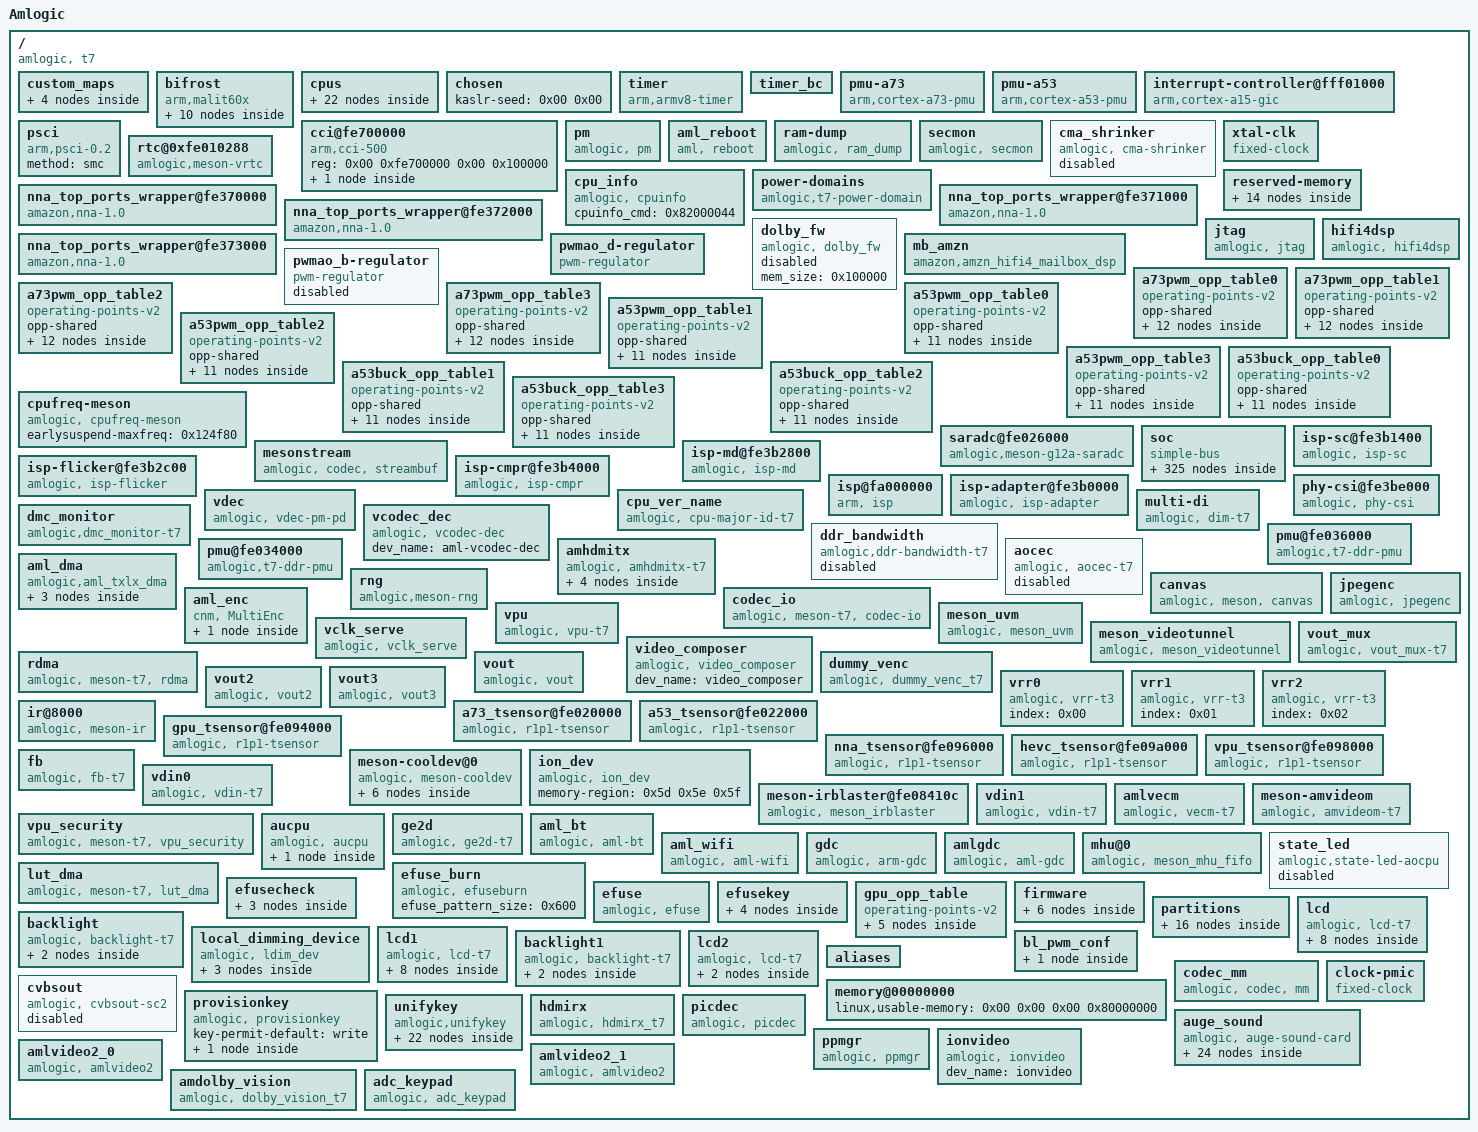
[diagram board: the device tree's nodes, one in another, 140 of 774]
/dts-v1/;

/ {
	model = "Amlogic";
	amlogic-dt-id = "t7_carmel_rev01";
	compatible = "amlogic, t7";
	interrupt-parent = <0x01>;
	#address-cells = <0x02>;
	#size-cells = <0x02>;

	custom_maps {
		mapnum = <0x04>;
		map0 = <0x02>;
		map1 = <0x03>;
		map2 = <0x04>;
		map3 = <0x05>;
		phandle = <0x5c>;

		map_0 {
			mapname = "amlogic-remote-1";
			customcode = <0xfb04>;
			release_delay = <0x50>;
			size = <0x33>;
			keymap = <0x47000b 0x130002 0x100003 0x110004 0xf0005 0xc0006 0xd0007 0xb0008 0x80009 0x9000a 0x5c0061 0x51003d 0x50003e 0x40003f 0x4d0040 0x430041 0x170042 0x43 0x10044 0x160057 0x49000e 0x60082 0x140083 0x440067 0x1d006c 0x1c0069 0x48006a 0x53007d 0x450068 0x19006d 0x520077 0x5007a 0x59007b 0x1b0078 0x40079 0x1a0074 0xa000f 0xe0071 0x1f0066 0x1e0084 0x70085 0x120086 0x540087 0x20088 0x4f001e 0x420030 0x5d002e 0x4c0020 0x580089 0x1500d9 0x55008c>;
			phandle = <0x02>;
		};

		map_1 {
			mapname = "amlogic-remote-2";
			customcode = <0xfe01>;
			release_delay = <0x50>;
			size = <0x35>;
			keymap = <0x10002 0x20003 0x30004 0x40005 0x50006 0x60007 0x70008 0x80009 0x9000a 0xa000b 0x1f01d2 0x15008b 0x16000f 0xc0192 0xd0193 0xe0073 0xf0072 0x110066 0x1c006a 0x1b0069 0x190067 0x1a006c 0x1d001c 0x170071 0x4900db 0x43009e 0x1201d5 0x1401d6 0x1801d7 0x590166 0x5a00a6 0x100074 0x4200a5 0x4400a3 0x1e00a8 0x4b00d0 0x5800a4 0x460082 0x400083 0x380046 0x5701d0 0x5b01d1 0x54018e 0x4c018f 0x4e0190 0x550191 0x5300ed 0x5200ee 0x3900d4 0x4100d5 0xb00d6 0xd8 0x1300d9>;
			phandle = <0x03>;
		};

		map_2 {
			mapname = "amlogic-remote-3";
			customcode = <0xbd02>;
			release_delay = <0x50>;
			size = <0x11>;
			keymap = <0xca0067 0xd2006c 0x990069 0xc1006a 0xce0061 0x450074 0xc50085 0x800071 0xd0000f 0xd6007d 0x950066 0xdd0068 0x8c006d 0x890083 0x9c0082 0x9a0078 0xcd0079>;
			phandle = <0x04>;
		};

		map_3 {
			mapname = "amlogic-remote-4";
			customcode = <0x7788>;
			release_delay = <0x50>;
			vendor = <0x02>;
			product = <0x02>;
			version = <0x200>;
			size = <0x26>;
			keymap = <0x10002 0x20003 0x30004 0x40005 0x50006 0x60007 0x70008 0x80009 0x9000a 0xa000b 0x5801d7 0x290166 0x74009c 0x4600d9 0xf008d 0x150067 0x16006c 0x170069 0x18006a 0x19001c 0x470066 0x48009e 0x32008a 0x210074 0x6001d2 0x250071 0x230073 0x240072 0x6300bb 0x6400bc 0x6700bd 0x6800be 0x330192 0x340193 0x4b018e 0x4a018f 0x490190 0x4c0191>;
			phandle = <0x05>;
		};
	};

	bifrost {
		compatible = "arm,malit60x\0arm,malit6xx\0arm,mali-midgard";
		#cooling-cells = <0x02>;
		reg = <0x00 0xfe400000 0x00 0x4000 0x00 0xfe002000 0x00 0x1000 0x00 0xff800000 0x00 0x1000 0x00 0xfe000000 0x00 0x1000 0x00 0xfe002000 0x00 0x1000>;
		interrupt-parent = <0x01>;
		interrupts = <0x00 0x90 0x04 0x00 0x91 0x04 0x00 0x92 0x04>;
		interrupt-names = "GPU\0MMU\0JOB";
		num_of_pp = <0x04>;
		sc_mpp = <0x01>;
		tbl = <0x06 0x07 0x08 0x09 0x0a 0x0a>;
		operating-points-v2 = <0x0b>;
		power-domains = <0x0c 0x1b>;
		system-coherency = <0x00>;
		clocks = <0x0d 0x8b>;
		clock-names = "gpu_mux";
		assigned-clocks = <0x0d 0x85 0x0d 0x87 0x0d 0x8b>;
		assigned-clock-parents = <0x0d 0x0f 0x00 0x0d 0x87>;
		assigned-clock-rates = <0x00 0x2faf0800 0x00>;

		clk125_cfg {
			clk_freq = <0x7735940>;
			clk_parent = "fclk_div4";
			clkp_freq = <0x1dcd6500>;
			clk_reg = <0xa03>;
			voltage = <0x47e>;
			keep_count = <0x05>;
			threshold = <0x1e 0x78>;
		};

		dvfs250_cfg {
			clk_freq = <0xee6b280>;
			clk_parent = "fclk_div4";
			clkp_freq = <0x1dcd6500>;
			clk_reg = <0xa01>;
			voltage = <0x47e>;
			keep_count = <0x05>;
			threshold = <0x00 0x4c>;
			phandle = <0x06>;
		};

		dvfs285_cfg {
			clk_freq = <0x1107a76d>;
			clk_parent = "fclk_div7";
			clkp_freq = <0x1107a76d>;
			clk_reg = <0xe00>;
			voltage = <0x47e>;
			keep_count = <0x05>;
			threshold = <0x00 0x4c>;
		};

		dvfs400_cfg {
			clk_freq = <0x17d78400>;
			clk_parent = "fclk_div5";
			clkp_freq = <0x17d78400>;
			clk_reg = <0xc00>;
			voltage = <0x47e>;
			keep_count = <0x05>;
			threshold = <0x50 0x78>;
			phandle = <0x07>;
		};

		dvfs500_cfg {
			clk_freq = <0x1dcd6500>;
			clk_parent = "fclk_div4";
			clkp_freq = <0x1dcd6500>;
			clk_reg = <0xa00>;
			voltage = <0x47e>;
			keep_count = <0x05>;
			threshold = <0x50 0x78>;
			phandle = <0x08>;
		};

		dvfs666_cfg {
			clk_freq = <0x27bc86aa>;
			clk_parent = "fclk_div3";
			clkp_freq = <0x27bc86aa>;
			clk_reg = <0x800>;
			voltage = <0x47e>;
			keep_count = <0x05>;
			threshold = <0x50 0x78>;
			phandle = <0x09>;
		};

		dvfs800_cfg {
			clk_freq = <0x2faf0800>;
			clk_parent = "fclk_div2p5";
			clkp_freq = <0x2faf0800>;
			clk_reg = <0x600>;
			voltage = <0x47e>;
			keep_count = <0x05>;
			threshold = <0x50 0xff>;
			phandle = <0x0a>;
		};

		dvfs850_cfg {
			clk_freq = <0x326cef80>;
			clk_parent = "gp0_pll";
			clkp_freq = <0x326cef80>;
			clk_reg = <0x200>;
			voltage = <0x47e>;
			keep_count = <0x05>;
			threshold = <0x50 0xff>;
		};

		reset_cfg {
			reg_level = <0x11>;
			reg_mask = <0x21>;
			reg_bit = <0x02>;
		};

		capb_reset {
			reg_level = <0x11>;
			reg_mask = <0x21>;
			reg_bit = <0x01>;
		};
	};

	cpus {
		#address-cells = <0x02>;
		#size-cells = <0x00>;

		cpu-map {

			cluster0 {

				core0 {
					cpu = <0x0e>;
				};

				core1 {
					cpu = <0x0f>;
				};

				core2 {
					cpu = <0x10>;
				};

				core3 {
					cpu = <0x11>;
				};
			};

			cluster1 {

				core0 {
					cpu = <0x12>;
				};

				core1 {
					cpu = <0x13>;
				};

				core2 {
					cpu = <0x14>;
				};

				core3 {
					cpu = <0x15>;
				};
			};
		};

		cpu@0 {
			device_type = "cpu";
			compatible = "arm,cortex-a73\0arm,armv8";
			reg = <0x00 0x00>;
			enable-method = "psci";
			cpu-idle-states = <0x16 0x17>;
			clocks = <0x0d 0x19 0x0d 0x18 0x0d 0x03>;
			clock-names = "core_clk\0low_freq_clk_parent\0high_freq_clk_parent";
			voltage-tolerance = <0x00>;
			clock-latency = <0xc350>;
			capacity-dmips-mhz = <0x400>;
			dynamic-power-coefficient = <0x226>;
			#cooling-cells = <0x02>;
			cpu-supply = <0x18>;
			multi_tables_available;
			operating-points-v2 = <0x19 0x1a 0x1b 0x1c>;
			phandle = <0x0e>;
		};

		cpu@1 {
			device_type = "cpu";
			compatible = "arm,cortex-a73\0arm,armv8";
			reg = <0x00 0x01>;
			enable-method = "psci";
			cpu-idle-states = <0x16 0x17>;
			clocks = <0x0d 0x19 0x0d 0x18 0x0d 0x03>;
			clock-names = "core_clk\0low_freq_clk_parent\0high_freq_clk_parent";
			voltage-tolerance = <0x00>;
			clock-latency = <0xc350>;
			capacity-dmips-mhz = <0x400>;
			dynamic-power-coefficient = <0x226>;
			#cooling-cells = <0x02>;
			cpu-supply = <0x18>;
			multi_tables_available;
			operating-points-v2 = <0x19 0x1a 0x1b 0x1c>;
			phandle = <0x0f>;
		};

		cpu@2 {
			device_type = "cpu";
			compatible = "arm,cortex-a73\0arm,armv8";
			reg = <0x00 0x02>;
			enable-method = "psci";
			cpu-idle-states = <0x16 0x17>;
			clocks = <0x0d 0x19 0x0d 0x18 0x0d 0x03>;
			clock-names = "core_clk\0low_freq_clk_parent\0high_freq_clk_parent";
			voltage-tolerance = <0x00>;
			clock-latency = <0xc350>;
			capacity-dmips-mhz = <0x400>;
			dynamic-power-coefficient = <0x226>;
			#cooling-cells = <0x02>;
			cpu-supply = <0x18>;
			multi_tables_available;
			operating-points-v2 = <0x19 0x1a 0x1b 0x1c>;
			phandle = <0x10>;
		};

		cpu@3 {
			device_type = "cpu";
			compatible = "arm,cortex-a73\0arm,armv8";
			reg = <0x00 0x03>;
			enable-method = "psci";
			cpu-idle-states = <0x16 0x17>;
			clocks = <0x0d 0x19 0x0d 0x18 0x0d 0x03>;
			clock-names = "core_clk\0low_freq_clk_parent\0high_freq_clk_parent";
			voltage-tolerance = <0x00>;
			clock-latency = <0xc350>;
			capacity-dmips-mhz = <0x400>;
			dynamic-power-coefficient = <0x226>;
			#cooling-cells = <0x02>;
			cpu-supply = <0x18>;
			multi_tables_available;
			operating-points-v2 = <0x19 0x1a 0x1b 0x1c>;
			phandle = <0x11>;
		};

		cpu@100 {
			device_type = "cpu";
			compatible = "arm,cortex-a53\0arm,armv8";
			reg = <0x00 0x100>;
			enable-method = "psci";
			cpu-idle-states = <0x16 0x17>;
			clocks = <0x0d 0x17 0x0d 0x16 0x0d 0x15>;
			clock-names = "core_clk\0low_freq_clk_parent\0high_freq_clk_parent";
			voltage-tolerance = <0x00>;
			clock-latency = <0xc350>;
			capacity-dmips-mhz = <0x278>;
			dynamic-power-coefficient = <0x6e>;
			#cooling-cells = <0x02>;
			cpu-supply = <0x1d>;
			cpu_reg_use_buck;
			multi_tables_available;
			operating-points-v2 = <0x1e 0x1f 0x20 0x21>;
			phandle = <0x12>;
		};

		cpu@101 {
			device_type = "cpu";
			compatible = "arm,cortex-a53\0arm,armv8";
			reg = <0x00 0x101>;
			enable-method = "psci";
			cpu-idle-states = <0x16 0x17>;
			clocks = <0x0d 0x17 0x0d 0x16 0x0d 0x15>;
			clock-names = "core_clk\0low_freq_clk_parent\0high_freq_clk_parent";
			voltage-tolerance = <0x00>;
			clock-latency = <0xc350>;
			capacity-dmips-mhz = <0x278>;
			dynamic-power-coefficient = <0x6e>;
			#cooling-cells = <0x02>;
			cpu-supply = <0x1d>;
			cpu_reg_use_buck;
			multi_tables_available;
			operating-points-v2 = <0x1e 0x1f 0x20 0x21>;
			phandle = <0x13>;
		};

		cpu@102 {
			device_type = "cpu";
			compatible = "arm,cortex-a53\0arm,armv8";
			reg = <0x00 0x102>;
			enable-method = "psci";
			cpu-idle-states = <0x16 0x17>;
			clocks = <0x0d 0x17 0x0d 0x16 0x0d 0x15>;
			clock-names = "core_clk\0low_freq_clk_parent\0high_freq_clk_parent";
			voltage-tolerance = <0x00>;
			clock-latency = <0xc350>;
			capacity-dmips-mhz = <0x278>;
			dynamic-power-coefficient = <0x6e>;
			#cooling-cells = <0x02>;
			cpu-supply = <0x1d>;
			cpu_reg_use_buck;
			multi_tables_available;
			operating-points-v2 = <0x1e 0x1f 0x20 0x21>;
			phandle = <0x14>;
		};

		cpu@103 {
			device_type = "cpu";
			compatible = "arm,cortex-a53\0arm,armv8";
			reg = <0x00 0x103>;
			enable-method = "psci";
			cpu-idle-states = <0x16 0x17>;
			clocks = <0x0d 0x17 0x0d 0x16 0x0d 0x15>;
			clock-names = "core_clk\0low_freq_clk_parent\0high_freq_clk_parent";
			voltage-tolerance = <0x00>;
			clock-latency = <0xc350>;
			capacity-dmips-mhz = <0x278>;
			dynamic-power-coefficient = <0x6e>;
			#cooling-cells = <0x02>;
			cpu-supply = <0x1d>;
			cpu_reg_use_buck;
			multi_tables_available;
			operating-points-v2 = <0x1e 0x1f 0x20 0x21>;
			phandle = <0x15>;
		};

		idle-states {
			entry-method = "arm,psci-0.2";

			cpu-sleep-0 {
				compatible = "arm,idle-state";
				arm,psci-suspend-param = <0x10000>;
				local-timer-stop;
				entry-latency-us = <0x1f4>;
				exit-latency-us = <0x3e8>;
				min-residency-us = <0x7d0>;
				phandle = <0x16>;
			};

			system-sleep-0 {
				compatible = "arm,idle-state";
				arm,psci-suspend-param = <0x00>;
				entry-latency-us = <0x3fffffff>;
				exit-latency-us = <0x40000000>;
				min-residency-us = <0xffffffff>;
				phandle = <0x17>;
			};
		};
	};

	chosen {
		kaslr-seed = <0x00 0x00>;
	};

	timer {
		compatible = "arm,armv8-timer";
		interrupts = <0x01 0x0d 0xff08 0x01 0x0e 0xff08 0x01 0x0b 0xff08 0x01 0x0a 0xff08>;
	};

	timer_bc {
		reg = <0x00 0xfe0100d8 0x00 0x04 0x00 0xfe0100dc 0x00 0x04>;
		timer_name = "Meson TimerD";
		clockevent-rating = <0x12c>;
		clockevent-shift = <0x14>;
		clockevent-features = <0x23>;
		interrupts = <0x00 0x03 0x01>;
		bit_enable = <0x07>;
		bit_mode = <0x06>;
		bit_resolution = <0x00>;
		resolution_1us = <0x01>;
		min_delta_ns = <0x0a>;
	};

	pmu-a73 {
		compatible = "arm,cortex-a73-pmu";
		private-interrupts;
		interrupts = <0x00 0x109 0x04 0x00 0x10a 0x04 0x00 0x10b 0x04 0x00 0x10c 0x04>;
		interrupt-affinity = <0x0e 0x0f 0x10 0x11>;
	};

	pmu-a53 {
		compatible = "arm,cortex-a53-pmu";
		private-interrupts;
		interrupts = <0x00 0xe9 0x04 0x00 0xea 0x04 0x00 0xeb 0x04 0x00 0xec 0x04>;
		interrupt-affinity = <0x12 0x13 0x14 0x15>;
	};

	interrupt-controller@fff01000 {
		compatible = "arm,cortex-a15-gic\0arm,cortex-a9-gic";
		#interrupt-cells = <0x03>;
		#address-cells = <0x00>;
		interrupt-controller;
		reg = <0x00 0xfff01000 0x00 0x1000 0x00 0xfff02000 0x00 0x100>;
		interrupts = <0x01 0x09 0xf04>;
		phandle = <0x01>;
	};

	cci@fe700000 {
		compatible = "arm,cci-500";
		#address-cells = <0x01>;
		#size-cells = <0x01>;
		reg = <0x00 0xfe700000 0x00 0x100000>;
		ranges = <0x00 0x00 0xfe700000 0x100000>;

		pmu@10000 {
			compatible = "arm,cci-500-pmu,r0";
			reg = <0x10000 0x80000>;
			interrupts = <0x00 0x4f 0x04 0x00 0x4f 0x04 0x00 0x4f 0x04 0x00 0x4f 0x04 0x00 0x4f 0x04 0x00 0x4f 0x04 0x00 0x4f 0x04 0x00 0x4f 0x04>;
		};
	};

	psci {
		compatible = "arm,psci-0.2";
		method = "smc";
	};

	pm {
		compatible = "amlogic, pm";
		status = "okay";
		device_name = "aml_pm";
		reg = <0x00 0xfe010288 0x00 0x04 0x00 0xfe0102dc 0x00 0x04>;
	};

	aml_reboot {
		compatible = "aml, reboot";
		sys_reset = <0x84000009>;
		sys_poweroff = <0x84000008>;
		dis_nb_cpus_in_shutdown;
	};

	ram-dump {
		compatible = "amlogic, ram_dump";
		status = "okay";
		reg = <0x00 0xfe0102d8 0x00 0x04>;
		reg-names = "SYSCTRL_STICKY_REG6";
		store_device = "data";
	};

	secmon {
		compatible = "amlogic, secmon";
		memory-region = <0x22>;
		in_base_func = <0x82000020>;
		out_base_func = <0x82000021>;
		inout_size_func = <0x8200002a>;
		reserve_mem_size = <0x3300000>;
		clear_range = <0x5100000 0x2a00000>;
	};

	cma_shrinker {
		compatible = "amlogic, cma-shrinker";
		status = "disabled";
		adj = <0x00 0x64 0xc8 0xfa 0x384 0x3b6>;
		free = <0x2000 0x3000 0x4000 0x6000 0x7000 0x8000>;
	};

	xtal-clk {
		compatible = "fixed-clock";
		clock-frequency = <0x16e3600>;
		clock-output-names = "xtal";
		#clock-cells = <0x00>;
		phandle = <0x2a>;
	};

	cpu_info {
		compatible = "amlogic, cpuinfo";
		status = "okay";
		cpuinfo_cmd = <0x82000044>;
	};

	rtc@0xfe010288 {
		compatible = "amlogic,meson-vrtc";
		reg = <0x00 0xfe010288 0x00 0x04>;
		status = "okay";
		mboxes = <0x23 0x05>;
	};

	power-domains {
		compatible = "amlogic,t7-power-domain";
		#power-domain-cells = <0x01>;
		status = "okay";
		phandle = <0x0c>;
	};

	reserved-memory {
		#address-cells = <0x02>;
		#size-cells = <0x02>;
		ranges;

		acenna_reserved {
			compatible = "shared-dma-pool";
			size = <0x00 0xb000000>;
			alloc-ranges = <0x00 0x00 0x00 0x80000000>;
			reusable;
			phandle = <0x24>;
		};

		ramoops@0x07400000 {
			compatible = "ramoops";
			reg = <0x00 0x7400000 0x00 0x100000>;
			record-size = <0x20000>;
			console-size = <0x40000>;
			ftrace-size = <0x80000>;
			pmsg-size = <0x20000>;
		};

		linux,secmon {
			compatible = "shared-dma-pool";
			reusable;
			size = <0x00 0x3400000>;
			alignment = <0x00 0x400000>;
			alloc-ranges = <0x00 0x5000000 0x00 0x3400000>;
			clear-map;
			phandle = <0x22>;
		};

		linux,dsp_fw {
			compatible = "shared-dma-pool";
			reusable;
			size = <0x00 0x1000000>;
			alignment = <0x00 0x400000>;
			alloc-ranges = <0x00 0x40000000 0x00 0x1000000>;
			phandle = <0x27>;
		};

		linux,meson-fb {
			compatible = "shared-dma-pool";
			reusable;
			size = <0x00 0x800000>;
			alignment = <0x00 0x400000>;
			alloc-ranges = <0x00 0x3f800000 0x00 0x800000>;
			phandle = <0x60>;
		};

		linux,codec_mm_cma {
			compatible = "shared-dma-pool";
			reusable;
			size = <0x00 0x1b000000>;
			alignment = <0x00 0x400000>;
			linux,contiguous-region;
			clear-map;
			phandle = <0x8c>;
		};

		linux,di_cma {
			compatible = "shared-dma-pool";
			reusable;
			size = <0x00 0xb000000>;
			alignment = <0x00 0x400000>;
		};

		linux,ppmgr {
			compatible = "shared-dma-pool";
			size = <0x00 0x00>;
			phandle = <0xb3>;
		};

		linux,ion-dev {
			compatible = "shared-dma-pool";
			reusable;
			size = <0x00 0xa000000>;
			alignment = <0x00 0x400000>;
			alloc-ranges = <0x00 0x00 0x40000000 0x40000000>;
			phandle = <0x5d>;
		};

		linux,ion-camera {
			compatible = "shared-dma-pool";
			reusable;
			size = <0x00 0x4000000>;
			alignment = <0x00 0x400000>;
			alloc-ranges = <0x00 0x00 0x40000000 0x40000000>;
			phandle = <0x5f>;
		};

		linux,ion-secure {
			compatible = "amlogic, ion-secure-mem";
			no-map;
			size = <0x00 0x00>;
			alignment = <0x00 0x400000>;
			phandle = <0x5e>;
		};

		linux,ion-fb {
			compatible = "shared-dma-pool";
			reusable;
			size = <0x00 0x1c00000>;
			alignment = <0x00 0x400000>;
		};

		linux,codec_mm_reserved {
			compatible = "amlogic, codec-mm-reserved";
			size = <0x00 0x00>;
			alignment = <0x00 0x100000>;
			phandle = <0x8d>;
		};

		linux,vdin1_cma {
			compatible = "shared-dma-pool";
			reusable;
			size = <0x00 0x1400000>;
			alignment = <0x00 0x400000>;
			phandle = <0x62>;
		};
	};

	nna_top_ports_wrapper@fe370000 {
		compatible = "amazon,nna-1.0";
		device-name = "acenna0";
		status = "okay";
		clocks = <0x0d 0x155>;
		clock-names = "nna_clk_gate";
		assigned-clocks = <0x0d 0x14e 0x0d 0x154 0x0d 0x155>;
		assigned-clock-parents = <0x0d 0x0f 0x0d 0x150 0x00>;
		assigned-clock-rates = <0x00 0x00 0x2faf0800>;
		interrupt-names = "nna_interrupt";
		interrupts = <0x00 0xb9 0x01>;
		memory-region = <0x24>;
		minor-number = <0x00>;
		power-domains = <0x0c 0x1e 0x0c 0x20>;
		power-domain-names = "pwrc-core\0pwrc-top";
		reg = <0x00 0xfe370000 0x00 0x1000>;
		reg-names = "nna_irq_wrapper";
	};

	nna_top_ports_wrapper@fe371000 {
		compatible = "amazon,nna-1.0";
		device-name = "acenna1";
		status = "okay";
		clocks = <0x0d 0x155>;
		clock-names = "nna_clk_gate";
		assigned-clocks = <0x0d 0x14e 0x0d 0x154 0x0d 0x155>;
		assigned-clock-parents = <0x0d 0x0f 0x0d 0x150 0x00>;
		assigned-clock-rates = <0x00 0x00 0x2faf0800>;
		interrupt-names = "nna_interrupt";
		interrupts = <0x00 0xba 0x01>;
		minor-number = <0x01>;
		power-domains = <0x0c 0x1f 0x0c 0x20>;
		power-domain-names = "pwrc-core\0pwrc-top";
		reg = <0x00 0xfe371000 0x00 0x1000>;
		reg-names = "nna_irq_wrapper";
	};

	nna_top_ports_wrapper@fe372000 {
		compatible = "amazon,nna-1.0";
		device-name = "acenna2";
		status = "okay";
		clocks = <0x0d 0x155>;
		clock-names = "nna_clk_gate";
		assigned-clocks = <0x0d 0x14e 0x0d 0x154 0x0d 0x155>;
		assigned-clock-parents = <0x0d 0x0f 0x0d 0x150 0x00>;
		assigned-clock-rates = <0x00 0x00 0x2faf0800>;
		interrupt-names = "nna_interrupt";
		interrupts = <0x00 0xbb 0x01>;
		minor-number = <0x02>;
		power-domains = <0x0c 0x1c 0x0c 0x20>;
		power-domain-names = "pwrc-core\0pwrc-top";
		reg = <0x00 0xfe372000 0x00 0x1000>;
		reg-names = "nna_irq_wrapper";
	};

	nna_top_ports_wrapper@fe373000 {
		compatible = "amazon,nna-1.0";
		device-name = "acenna3";
		status = "okay";
		clocks = <0x0d 0x155>;
		clock-names = "nna_clk_gate";
		assigned-clocks = <0x0d 0x14e 0x0d 0x154 0x0d 0x155>;
		assigned-clock-parents = <0x0d 0x0f 0x0d 0x150 0x00>;
		assigned-clock-rates = <0x00 0x00 0x2faf0800>;
		interrupt-names = "nna_interrupt";
		interrupts = <0x00 0xbc 0x01>;
		minor-number = <0x03>;
		power-domains = <0x0c 0x1d 0x0c 0x20>;
		power-domain-names = "pwrc-core\0pwrc-top";
		reg = <0x00 0xfe373000 0x00 0x1000>;
		reg-names = "nna_irq_wrapper";
	};

	dolby_fw {
		compatible = "amlogic, dolby_fw";
		mem_size = <0x100000>;
		status = "disabled";
	};

	jtag {
		compatible = "amlogic, jtag";
		status = "okay";
		select = "disable";
		pinctrl-names = "jtag_a_pins\0jtag_b_pins";
		pinctrl-0 = <0x25>;
		pinctrl-1 = <0x26>;
	};

	hifi4dsp {
		compatible = "amlogic, hifi4dsp";
		memory-region = <0x27>;
		reg = <0x00 0xfe340018 0x00 0x114 0x00 0xfe350018 0x00 0x114 0x00 0xfe010258 0x00 0x04 0x00 0xfe01025c 0x00 0x04 0x00 0x40b80000 0x00 0x80000>;
		dsp-monitor-period-ms = <0x3e8>;
		reg-names = "dspa_top_reg\0dspb_top_reg";
		clocks = <0x0d 0x55 0x0d 0x133>;
		clock-names = "dspa_clk\0dspb_clk";
		dsp-start-mode = <0x01>;
		dsp-cnt = <0x02>;
		dspaoffset = <0x00>;
		dspboffset = <0xc00000>;
		bootlocation = <0x01>;
		optimize_longcall = <0x01 0x01>;
		sram_remap_addr = <0x42000000 0xf7000000 0x42100000 0xf7100000>;
		boot_sram_addr = <0xfff00000>;
		boot_sram_size = <0x80000>;
		power-domains = <0x0c 0x00 0x0c 0x01>;
		power-domain-names = "dspa\0dspb";
		status = "okay";
	};

	mb_amzn {
		status = "okay";
		compatible = "amazon,amzn_hifi4_mailbox_dsp";
	};

	pwmao_d-regulator {
		compatible = "pwm-regulator";
		pwms = <0x28 0x01 0x5dc 0x00>;
		regulator-name = "vddcpua";
		regulator-min-microvolt = <0xa8368>;
		regulator-max-microvolt = <0x1001a8>;
		regulator-always-on;
		max-duty-cycle = <0x5dc>;
		voltage-table = <0x1001a8 0x00 0xfda98 0x03 0xfb388 0x06 0xf8c78 0x09 0xf6568 0x0c 0xf3e58 0x0e 0xf1748 0x11 0xef038 0x14 0xec928 0x17 0xea218 0x1a 0xe7b08 0x1d 0xe53f8 0x1f 0xe2ce8 0x22 0xe05d8 0x25 0xddec8 0x28 0xdb7b8 0x2b 0xd90a8 0x2d 0xd6998 0x30 0xd4288 0x33 0xd1b78 0x36 0xcf468 0x38 0xccd58 0x3b 0xca648 0x3e 0xc7f38 0x41 0xc5828 0x44 0xc3118 0x46 0xc0a08 0x49 0xbe2f8 0x4c 0xbbbe8 0x4f 0xb94d8 0x51 0xb6dc8 0x54 0xb46b8 0x57 0xb1fa8 0x59 0xaf898 0x5c 0xad188 0x5f 0xaaa78 0x62 0xa8368 0x64>;
		status = "okay";
		phandle = <0x18>;
	};

	pwmao_b-regulator {
		compatible = "pwm-regulator";
		pwms = <0x29 0x01 0x5dc 0x00>;
		regulator-name = "vddcpub";
		regulator-min-microvolt = <0xa8368>;
		regulator-max-microvolt = <0x1001a8>;
		regulator-always-on;
		max-duty-cycle = <0x5dc>;
		voltage-table = <0x1001a8 0x00 0xfda98 0x03 0xfb388 0x06 0xf8c78 0x09 0xf6568 0x0c 0xf3e58 0x0e 0xf1748 0x11 0xef038 0x14 0xec928 0x17 0xea218 0x1a 0xe7b08 0x1d 0xe53f8 0x1f 0xe2ce8 0x22 0xe05d8 0x25 0xddec8 0x28 0xdb7b8 0x2b 0xd90a8 0x2d 0xd6998 0x30 0xd4288 0x33 0xd1b78 0x36 0xcf468 0x38 0xccd58 0x3b 0xca648 0x3e 0xc7f38 0x41 0xc5828 0x44 0xc3118 0x46 0xc0a08 0x49 0xbe2f8 0x4c 0xbbbe8 0x4f 0xb94d8 0x51 0xb6dc8 0x54 0xb46b8 0x57 0xb1fa8 0x59 0xaf898 0x5c 0xad188 0x5f 0xaaa78 0x62 0xa8368 0x64>;
		status = "disabled";
	};

	a73pwm_opp_table0 {
		compatible = "operating-points-v2";
		opp-shared;
		phandle = <0x19>;

		opp00 {
			opp-hz = <0x00 0x1dcd6500>;
			opp-microvolt = <0xc7f38>;
		};

		opp01 {
			opp-hz = <0x00 0x27b25a80>;
			opp-microvolt = <0xc7f38>;
		};

		opp02 {
			opp-hz = <0x00 0x3b9aca00>;
			opp-microvolt = <0xc7f38>;
		};

		opp03 {
			opp-hz = <0x00 0x47868c00>;
			opp-microvolt = <0xc7f38>;
		};

		opp04 {
			opp-hz = <0x00 0x52f83c00>;
			opp-microvolt = <0xc7f38>;
		};

		opp05 {
			opp-hz = <0x00 0x5a1f4a00>;
			opp-microvolt = <0xca648>;
		};

		opp06 {
			opp-hz = <0x00 0x5fd82200>;
			opp-microvolt = <0xcf468>;
		};

		opp07 {
			opp-hz = <0x00 0x6590fa00>;
			opp-microvolt = <0xd4288>;
		};

		opp08 {
			opp-hz = <0x00 0x6b49d200>;
			opp-microvolt = <0xddec8>;
		};

		opp09 {
			opp-hz = <0x00 0x7102aa00>;
			opp-microvolt = <0xe53f8>;
		};

		opp10 {
			opp-hz = <0x00 0x7829b800>;
			opp-microvolt = <0xea218>;
		};

		opp11 {
			opp-hz = <0x00 0x839b6800>;
			opp-microvolt = <0xf6568>;
		};
	};

	a73pwm_opp_table1 {
		compatible = "operating-points-v2";
		opp-shared;
		phandle = <0x1a>;

		opp00 {
			opp-hz = <0x00 0x1dcd6500>;
			opp-microvolt = <0xc7f38>;
		};

		opp01 {
			opp-hz = <0x00 0x27b25a80>;
			opp-microvolt = <0xc7f38>;
		};

		opp02 {
			opp-hz = <0x00 0x3b9aca00>;
			opp-microvolt = <0xc7f38>;
		};

		opp03 {
			opp-hz = <0x00 0x47868c00>;
			opp-microvolt = <0xc7f38>;
		};

		opp04 {
			opp-hz = <0x00 0x52f83c00>;
			opp-microvolt = <0xc7f38>;
		};

		opp05 {
			opp-hz = <0x00 0x5a1f4a00>;
			opp-microvolt = <0xca648>;
		};

		opp06 {
			opp-hz = <0x00 0x5fd82200>;
			opp-microvolt = <0xcf468>;
		};

		opp07 {
			opp-hz = <0x00 0x6590fa00>;
			opp-microvolt = <0xd4288>;
		};

		opp08 {
			opp-hz = <0x00 0x6b49d200>;
			opp-microvolt = <0xddec8>;
		};

		opp09 {
			opp-hz = <0x00 0x7102aa00>;
			opp-microvolt = <0xe53f8>;
		};

		opp10 {
			opp-hz = <0x00 0x7829b800>;
			opp-microvolt = <0xea218>;
		};

		opp11 {
			opp-hz = <0x00 0x839b6800>;
			opp-microvolt = <0xf6568>;
		};
	};

	a73pwm_opp_table2 {
		compatible = "operating-points-v2";
		opp-shared;
		phandle = <0x1b>;

		opp00 {
			opp-hz = <0x00 0x1dcd6500>;
			opp-microvolt = <0xc3118>;
		};

		opp01 {
			opp-hz = <0x00 0x27b25a80>;
			opp-microvolt = <0xc3118>;
		};

		opp02 {
			opp-hz = <0x00 0x3b9aca00>;
			opp-microvolt = <0xc3118>;
		};

		opp03 {
			opp-hz = <0x00 0x47868c00>;
			opp-microvolt = <0xc3118>;
		};

		opp04 {
			opp-hz = <0x00 0x52f83c00>;
			opp-microvolt = <0xc5828>;
		};

		opp05 {
			opp-hz = <0x00 0x5a1f4a00>;
			opp-microvolt = <0xc5828>;
		};

		opp06 {
			opp-hz = <0x00 0x5fd82200>;
			opp-microvolt = <0xca648>;
		};

		opp07 {
			opp-hz = <0x00 0x6590fa00>;
			opp-microvolt = <0xcf468>;
		};

		opp08 {
			opp-hz = <0x00 0x6b49d200>;
			opp-microvolt = <0xd1b78>;
		};

		opp09 {
			opp-hz = <0x00 0x7102aa00>;
			opp-microvolt = <0xd90a8>;
		};

		opp10 {
			opp-hz = <0x00 0x7829b800>;
			opp-microvolt = <0xe05d8>;
		};

		opp11 {
			opp-hz = <0x00 0x839b6800>;
			opp-microvolt = <0xec928>;
		};
	};

	a73pwm_opp_table3 {
		compatible = "operating-points-v2";
		opp-shared;
		phandle = <0x1c>;

		opp00 {
			opp-hz = <0x00 0x1dcd6500>;
			opp-microvolt = <0xc0a08>;
		};

		opp01 {
			opp-hz = <0x00 0x27b25a80>;
			opp-microvolt = <0xc0a08>;
		};

		opp02 {
			opp-hz = <0x00 0x3b9aca00>;
			opp-microvolt = <0xc0a08>;
		};

		opp03 {
			opp-hz = <0x00 0x47868c00>;
			opp-microvolt = <0xc0a08>;
		};

		opp04 {
			opp-hz = <0x00 0x52f83c00>;
			opp-microvolt = <0xc5828>;
		};

		opp05 {
			opp-hz = <0x00 0x5a1f4a00>;
			opp-microvolt = <0xc5828>;
		};

		opp06 {
			opp-hz = <0x00 0x5fd82200>;
			opp-microvolt = <0xc7f38>;
		};

		opp07 {
			opp-hz = <0x00 0x6590fa00>;
			opp-microvolt = <0xca648>;
		};

		opp08 {
			opp-hz = <0x00 0x6b49d200>;
			opp-microvolt = <0xcf468>;
		};

		opp09 {
			opp-hz = <0x00 0x7102aa00>;
			opp-microvolt = <0xd1b78>;
		};

		opp10 {
			opp-hz = <0x00 0x7829b800>;
			opp-microvolt = <0xd6998>;
		};

		opp11 {
			opp-hz = <0x00 0x839b6800>;
			opp-microvolt = <0xe05d8>;
		};
	};

	a53pwm_opp_table0 {
		compatible = "operating-points-v2";
		opp-shared;

		opp00 {
			opp-hz = <0x00 0x1dcd6500>;
			opp-microvolt = <0xbbbe8>;
		};

		opp01 {
			opp-hz = <0x00 0x27b25a80>;
			opp-microvolt = <0xbbbe8>;
		};

		opp02 {
			opp-hz = <0x00 0x3b9aca00>;
			opp-microvolt = <0xbbbe8>;
		};

		opp03 {
			opp-hz = <0x00 0x47868c00>;
			opp-microvolt = <0xbbbe8>;
		};

		opp04 {
			opp-hz = <0x00 0x52f83c00>;
			opp-microvolt = <0xbbbe8>;
		};

		opp05 {
			opp-hz = <0x00 0x5a1f4a00>;
			opp-microvolt = <0xc5828>;
		};

		opp06 {
			opp-hz = <0x00 0x5fd82200>;
			opp-microvolt = <0xccd58>;
		};

		opp07 {
			opp-hz = <0x00 0x6590fa00>;
			opp-microvolt = <0xd4288>;
		};

		opp08 {
			opp-hz = <0x00 0x6b49d200>;
			opp-microvolt = <0xddec8>;
		};

		opp09 {
			opp-hz = <0x00 0x7102aa00>;
			opp-microvolt = <0xe7b08>;
		};

		opp10 {
			opp-hz = <0x00 0x7829b800>;
			opp-microvolt = <0xf6568>;
		};
	};

	a53pwm_opp_table1 {
		compatible = "operating-points-v2";
		opp-shared;

		opp00 {
			opp-hz = <0x00 0x1dcd6500>;
			opp-microvolt = <0xbbbe8>;
		};

		opp01 {
			opp-hz = <0x00 0x27b25a80>;
			opp-microvolt = <0xbbbe8>;
		};

		opp02 {
			opp-hz = <0x00 0x3b9aca00>;
			opp-microvolt = <0xbbbe8>;
		};

		opp03 {
			opp-hz = <0x00 0x47868c00>;
			opp-microvolt = <0xbbbe8>;
		};

		opp04 {
			opp-hz = <0x00 0x52f83c00>;
			opp-microvolt = <0xbbbe8>;
		};

		opp05 {
			opp-hz = <0x00 0x5a1f4a00>;
			opp-microvolt = <0xc5828>;
		};

		opp06 {
			opp-hz = <0x00 0x5fd82200>;
			opp-microvolt = <0xccd58>;
		};

		opp07 {
			opp-hz = <0x00 0x6590fa00>;
			opp-microvolt = <0xd4288>;
		};

		opp08 {
			opp-hz = <0x00 0x6b49d200>;
			opp-microvolt = <0xddec8>;
		};

		opp09 {
			opp-hz = <0x00 0x7102aa00>;
			opp-microvolt = <0xe7b08>;
		};

		opp10 {
			opp-hz = <0x00 0x7829b800>;
			opp-microvolt = <0xf6568>;
		};
	};

	a53pwm_opp_table2 {
		compatible = "operating-points-v2";
		opp-shared;

		opp00 {
			opp-hz = <0x00 0x1dcd6500>;
			opp-microvolt = <0xb94d8>;
		};

		opp01 {
			opp-hz = <0x00 0x27b25a80>;
			opp-microvolt = <0xb94d8>;
		};

		opp02 {
			opp-hz = <0x00 0x3b9aca00>;
			opp-microvolt = <0xb94d8>;
		};

		opp03 {
			opp-hz = <0x00 0x47868c00>;
			opp-microvolt = <0xb94d8>;
		};

		opp04 {
			opp-hz = <0x00 0x52f83c00>;
			opp-microvolt = <0xbbbe8>;
		};

		opp05 {
			opp-hz = <0x00 0x5a1f4a00>;
			opp-microvolt = <0xc0a08>;
		};

		opp06 {
			opp-hz = <0x00 0x5fd82200>;
			opp-microvolt = <0xc3118>;
		};

		opp07 {
			opp-hz = <0x00 0x6590fa00>;
			opp-microvolt = <0xca648>;
		};

		opp08 {
			opp-hz = <0x00 0x6b49d200>;
			opp-microvolt = <0xd1b78>;
		};

		opp09 {
			opp-hz = <0x00 0x7102aa00>;
			opp-microvolt = <0xdb7b8>;
		};

		opp10 {
			opp-hz = <0x00 0x7829b800>;
			opp-microvolt = <0xe7b08>;
		};
	};

	a53pwm_opp_table3 {
		compatible = "operating-points-v2";
		opp-shared;

		opp00 {
			opp-hz = <0x00 0x1dcd6500>;
			opp-microvolt = <0xb6dc8>;
		};

		opp01 {
			opp-hz = <0x00 0x27b25a80>;
			opp-microvolt = <0xb6dc8>;
		};

		opp02 {
			opp-hz = <0x00 0x3b9aca00>;
			opp-microvolt = <0xb6dc8>;
		};

		opp03 {
			opp-hz = <0x00 0x47868c00>;
			opp-microvolt = <0xb6dc8>;
		};

		opp04 {
			opp-hz = <0x00 0x52f83c00>;
			opp-microvolt = <0xbbbe8>;
		};

		opp05 {
			opp-hz = <0x00 0x5a1f4a00>;
			opp-microvolt = <0xbe2f8>;
		};

		opp06 {
			opp-hz = <0x00 0x5fd82200>;
			opp-microvolt = <0xc0a08>;
		};

		opp07 {
			opp-hz = <0x00 0x6590fa00>;
			opp-microvolt = <0xc5828>;
		};

		opp08 {
			opp-hz = <0x00 0x6b49d200>;
			opp-microvolt = <0xca648>;
		};

		opp09 {
			opp-hz = <0x00 0x7102aa00>;
			opp-microvolt = <0xd1b78>;
		};

		opp10 {
			opp-hz = <0x00 0x7829b800>;
			opp-microvolt = <0xe05d8>;
		};
	};

	a53buck_opp_table0 {
		compatible = "operating-points-v2";
		opp-shared;
		phandle = <0x1e>;

		opp00 {
			opp-hz = <0x00 0x1dcd6500>;
			opp-microvolt = <0xbbfd0>;
		};

		opp01 {
			opp-hz = <0x00 0x27b25a80>;
			opp-microvolt = <0xbbfd0>;
		};

		opp02 {
			opp-hz = <0x00 0x3b9aca00>;
			opp-microvolt = <0xbbfd0>;
		};

		opp03 {
			opp-hz = <0x00 0x47868c00>;
			opp-microvolt = <0xbbfd0>;
		};

		opp04 {
			opp-hz = <0x00 0x52f83c00>;
			opp-microvolt = <0xbbfd0>;
		};

		opp05 {
			opp-hz = <0x00 0x5a1f4a00>;
			opp-microvolt = <0xc5c10>;
		};

		opp06 {
			opp-hz = <0x00 0x5fd82200>;
			opp-microvolt = <0xcd140>;
		};

		opp07 {
			opp-hz = <0x00 0x6590fa00>;
			opp-microvolt = <0xd4670>;
		};

		opp08 {
			opp-hz = <0x00 0x6b49d200>;
			opp-microvolt = <0xde2b0>;
		};

		opp09 {
			opp-hz = <0x00 0x7102aa00>;
			opp-microvolt = <0xe7ef0>;
		};

		opp10 {
			opp-hz = <0x00 0x7829b800>;
			opp-microvolt = <0xf6950>;
		};
	};

	a53buck_opp_table1 {
		compatible = "operating-points-v2";
		opp-shared;
		phandle = <0x1f>;

		opp00 {
			opp-hz = <0x00 0x1dcd6500>;
			opp-microvolt = <0xbbfd0>;
		};

		opp01 {
			opp-hz = <0x00 0x27b25a80>;
			opp-microvolt = <0xbbfd0>;
		};

		opp02 {
			opp-hz = <0x00 0x3b9aca00>;
			opp-microvolt = <0xbbfd0>;
		};

		opp03 {
			opp-hz = <0x00 0x47868c00>;
			opp-microvolt = <0xbbfd0>;
		};

		opp04 {
			opp-hz = <0x00 0x52f83c00>;
			opp-microvolt = <0xbbfd0>;
		};

		opp05 {
			opp-hz = <0x00 0x5a1f4a00>;
			opp-microvolt = <0xc5c10>;
		};

		opp06 {
			opp-hz = <0x00 0x5fd82200>;
			opp-microvolt = <0xcd140>;
		};

		opp07 {
			opp-hz = <0x00 0x6590fa00>;
			opp-microvolt = <0xd4670>;
		};

		opp08 {
			opp-hz = <0x00 0x6b49d200>;
			opp-microvolt = <0xde2b0>;
		};

		opp09 {
			opp-hz = <0x00 0x7102aa00>;
			opp-microvolt = <0xe7ef0>;
		};

		opp10 {
			opp-hz = <0x00 0x7829b800>;
			opp-microvolt = <0xf6950>;
		};
	};

	a53buck_opp_table2 {
		compatible = "operating-points-v2";
		opp-shared;
		phandle = <0x20>;

		opp00 {
			opp-hz = <0x00 0x1dcd6500>;
			opp-microvolt = <0xb98c0>;
		};

		opp01 {
			opp-hz = <0x00 0x27b25a80>;
			opp-microvolt = <0xb98c0>;
		};

		opp02 {
			opp-hz = <0x00 0x3b9aca00>;
			opp-microvolt = <0xb98c0>;
		};

		opp03 {
			opp-hz = <0x00 0x47868c00>;
			opp-microvolt = <0xb98c0>;
		};

		opp04 {
			opp-hz = <0x00 0x52f83c00>;
			opp-microvolt = <0xbbfd0>;
		};

		opp05 {
			opp-hz = <0x00 0x5a1f4a00>;
			opp-microvolt = <0xc0df0>;
		};

		opp06 {
			opp-hz = <0x00 0x5fd82200>;
			opp-microvolt = "\0\f5";
		};

		opp07 {
			opp-hz = <0x00 0x6590fa00>;
			opp-microvolt = <0xcaa30>;
		};

		opp08 {
			opp-hz = <0x00 0x6b49d200>;
			opp-microvolt = <0xd1f60>;
		};

		opp09 {
			opp-hz = <0x00 0x7102aa00>;
			opp-microvolt = <0xdbba0>;
		};

		opp10 {
			opp-hz = <0x00 0x7829b800>;
			opp-microvolt = <0xe7ef0>;
		};
	};

	a53buck_opp_table3 {
		compatible = "operating-points-v2";
		opp-shared;
		phandle = <0x21>;

		opp00 {
			opp-hz = <0x00 0x1dcd6500>;
			opp-microvolt = <0xb71b0>;
		};

		opp01 {
			opp-hz = <0x00 0x27b25a80>;
			opp-microvolt = <0xb71b0>;
		};

		opp02 {
			opp-hz = <0x00 0x3b9aca00>;
			opp-microvolt = <0xb71b0>;
		};

		opp03 {
			opp-hz = <0x00 0x47868c00>;
			opp-microvolt = <0xb71b0>;
		};

		opp04 {
			opp-hz = <0x00 0x52f83c00>;
			opp-microvolt = <0xbbfd0>;
		};

		opp05 {
			opp-hz = <0x00 0x5a1f4a00>;
			opp-microvolt = <0xbe6e0>;
		};

		opp06 {
			opp-hz = <0x00 0x5fd82200>;
			opp-microvolt = <0xc0df0>;
		};

		opp07 {
			opp-hz = <0x00 0x6590fa00>;
			opp-microvolt = <0xc5c10>;
		};

		opp08 {
			opp-hz = <0x00 0x6b49d200>;
			opp-microvolt = <0xcaa30>;
		};

		opp09 {
			opp-hz = <0x00 0x7102aa00>;
			opp-microvolt = <0xd1f60>;
		};

		opp10 {
			opp-hz = <0x00 0x7829b800>;
			opp-microvolt = <0xe09c0>;
		};
	};

	cpufreq-meson {
		compatible = "amlogic, cpufreq-meson";
		earlysuspend-maxfreq = <0x124f80>;
		status = "okay";
	};

	saradc@fe026000 {
		compatible = "amlogic,meson-g12a-saradc\0amlogic,meson-saradc";
		status = "okay";
		#io-channel-cells = <0x01>;
		clocks = <0x2a 0x0d 0x1aa 0x0d 0x129 0x0d 0x127>;
		clock-names = "clkin\0core\0adc_clk\0adc_sel";
		interrupts = <0x00 0xb5 0x01>;
		reg = <0x00 0xfe026000 0x00 0x48>;
		phandle = <0xb4>;
	};

	soc {
		compatible = "simple-bus";
		#address-cells = <0x02>;
		#size-cells = <0x02>;
		ranges;

		apb4@fe000000 {
			compatible = "simple-bus";
			reg = <0x00 0xfe000000 0x00 0x480000>;
			#address-cells = <0x02>;
			#size-cells = <0x02>;
			ranges = <0x00 0x00 0x00 0xfe000000 0x00 0x480000>;

			clock-controller {
				compatible = "amlogic,t7-clkc";
				#clock-cells = <0x01>;
				reg = <0x00 0x00 0x00 0x49c 0x00 0x8000 0x00 0x320 0x00 0xe040 0x00 0xbc>;
				reg-names = "basic\0pll\0cpu_clk";
				clocks = <0x2a>;
				clock-names = "xtal";
				status = "okay";
				phandle = <0x0d>;
			};

			meson_clk_msr@48000 {
				compatible = "amlogic,meson-t7-clk-measure";
				reg = <0x00 0x48000 0x00 0x1c>;
			};

			meson_ring_msr {
				compatible = "amlogic,meson-t7-ring-msr";
				status = "okay";
			};

			watchdog@2100 {
				compatible = "amlogic,meson-sc2-wdt";
				status = "okay";
				amlogic,feed_watchdog_mode = <0x01>;
				reg = <0x00 0x2100 0x00 0x10>;
				clocks = <0x2a>;
			};

			pinctrl@4000 {
				compatible = "amlogic,meson-t7-periphs-pinctrl";
				#address-cells = <0x02>;
				#size-cells = <0x02>;
				ranges;
				phandle = <0x2b>;

				bank@4000 {
					reg = <0x00 0x4000 0x00 0x64 0x00 0x40c0 0x00 0x220>;
					reg-names = "mux\0gpio";
					gpio-controller;
					#gpio-cells = <0x02>;
					gpio-ranges = <0x2b 0x00 0x00 0x9d>;
					phandle = <0x2d>;
				};

				i2c0_pins1 {

					mux {
						groups = "i2c0_sda_t\0i2c0_sck_t";
						function = "i2c0";
						drive-strength-microamp = <0xbb8>;
						bias-disable;
					};
				};

				i2c0_pins2 {

					mux {
						groups = "i2c0_sda_h\0i2c0_sck_h";
						function = "i2c0";
						drive-strength-microamp = <0xbb8>;
						bias-disable;
					};
				};

				i2c1_pins1 {
					phandle = <0x31>;

					mux {
						groups = "i2c1_sda\0i2c1_sck";
						function = "i2c1";
						drive-strength-microamp = <0x1f4>;
						bias-disable;
					};
				};

				i2c2_pins1 {

					mux {
						groups = "i2c2_sda_x\0i2c2_sck_x";
						function = "i2c2";
						drive-strength-microamp = <0xbb8>;
						bias-disable;
					};
				};

				i2c2_pins2 {

					mux {
						groups = "i2c2_sda_t\0i2c2_sck_t";
						function = "i2c2";
						drive-strength-microamp = <0xbb8>;
						bias-disable;
					};
				};

				i2c2_pins3 {

					mux {
						groups = "i2c2_sda_m\0i2c2_sck_m";
						function = "i2c2";
						drive-strength-microamp = <0xbb8>;
						bias-disable;
					};
				};

				i2c3_pins1 {

					mux {
						groups = "i2c3_sda_m\0i2c3_sck_m";
						function = "i2c3";
						drive-strength-microamp = <0xbb8>;
						bias-disable;
					};
				};

				i2c3_pins2 {

					mux {
						groups = "i2c3_sda_h\0i2c3_sck_h";
						function = "i2c3";
						drive-strength-microamp = <0x1f4>;
						bias-disable;
					};
				};

				i2c4_pins1 {

					mux {
						groups = "i2c4_sda_y\0i2c4_sck_y";
						function = "i2c4";
						drive-strength-microamp = <0xbb8>;
						bias-disable;
					};
				};

				i2c4_pins2 {

					mux {
						groups = "i2c4_sda_h\0i2c4_sck_h";
						function = "i2c4";
						drive-strength-microamp = <0xbb8>;
						bias-disable;
					};
				};

				i2c5_pins1 {

					mux {
						groups = "i2c5_sda\0i2c5_sck";
						function = "i2c5";
						drive-strength-microamp = <0xbb8>;
						bias-disable;
					};
				};

				i2c0_ao_pins1 {
					phandle = <0x32>;

					mux {
						groups = "i2c0_ao_sda_d\0i2c0_ao_sck_d";
						function = "i2c0_ao";
						drive-strength-microamp = <0xbb8>;
						bias-disable;
					};
				};

				i2c0_ao_pins2 {

					mux {
						groups = "i2c0_ao_sda_e\0i2c0_ao_sck_e";
						function = "i2c0_ao";
						drive-strength-microamp = <0xbb8>;
						bias-disable;
					};
				};

				i2c1_ao_pins1 {

					mux {
						groups = "i2c1_ao_sda\0i2c1_ao_sck";
						function = "i2c1_ao";
						drive-strength-microamp = <0xbb8>;
						bias-disable;
					};
				};

				a_uart1 {

					mux {
						groups = "uart_a_tx_d2\0uart_a_rx_d3";
						function = "uart_a";
					};
				};

				a_uart2 {

					mux {
						groups = "uart_a_tx_d8\0uart_a_rx_d9";
						function = "uart_a";
					};
				};

				b_uart {
					phandle = <0x35>;

					mux {
						groups = "uart_ao_b_tx\0uart_ao_b_rx";
						function = "uart_ao_b";
					};
				};

				c_uart {
					phandle = <0x4e>;

					mux {
						groups = "uart_c_tx\0uart_c_rx\0uart_c_cts\0uart_c_rts";
						bias-pull-up;
						output-high;
						function = "uart_c";
					};
				};

				d_uart1 {
					phandle = <0x4f>;

					mux {
						groups = "uart_d_tx_m\0uart_d_rx_m";
						function = "uart_d";
					};
				};

				d_uart2 {

					mux {
						groups = "uart_d_tx_y\0uart_d_rx_y";
						function = "uart_d";
					};
				};

				e_uart {
					phandle = <0x50>;

					mux {
						groups = "uart_e_tx\0uart_e_rx\0uart_e_cts\0uart_e_rts";
						bias-pull-up;
						output-high;
						function = "uart_e";
					};
				};

				f_uart {
					phandle = <0x51>;

					mux {
						groups = "uart_f_tx\0uart_f_rx";
						function = "uart_f";
					};
				};

				emmc {
					phandle = <0x45>;

					mux-0 {
						groups = "emmc_nand_d0\0emmc_nand_d1\0emmc_nand_d2\0emmc_nand_d3\0emmc_nand_d4\0emmc_nand_d5\0emmc_nand_d6\0emmc_nand_d7\0emmc_cmd";
						function = "emmc";
						bias-pull-up;
						drive-strength-microamp = <0xfa0>;
					};

					mux-1 {
						groups = "emmc_clk";
						function = "emmc";
						bias-disable;
						drive-strength-microamp = <0xfa0>;
					};
				};

				emmc-ds {
					phandle = <0x46>;

					mux {
						groups = "emmc_nand_ds";
						function = "emmc";
						bias-pull-down;
						drive-strength-microamp = <0xfa0>;
					};
				};

				emmc_clk_gate {
					phandle = <0x47>;

					mux {
						groups = "GPIOB_8";
						function = "gpio_periphs";
						bias-pull-down;
						drive-strength-microamp = <0xfa0>;
					};
				};

				sd_clk_cmd_pins {

					mux {
						groups = "sdcard_cmd";
						function = "sdcard";
						bias-pull-up;
						drive-strength-microamp = <0xfa0>;
					};

					mux1 {
						groups = "sdcard_clk";
						function = "sdcard";
						bias-pull-up;
						drive-strength-microamp = <0xfa0>;
					};
				};

				sd_all_pins {
					phandle = <0x48>;

					mux {
						groups = "sdcard_d0\0sdcard_d1\0sdcard_d2\0sdcard_d3\0sdcard_cmd";
						function = "sdcard";
						bias-pull-up;
						drive-strength-microamp = <0xfa0>;
					};

					mux1 {
						groups = "sdcard_clk";
						function = "sdcard";
						bias-pull-up;
						drive-strength-microamp = <0xfa0>;
					};
				};

				sd_clk_gate {
					phandle = <0x4a>;

					mux {
						groups = "GPIOC_4";
						function = "gpio_periphs";
						bias-pull-down;
						drive-strength-microamp = <0xfa0>;
					};
				};

				sd_all_pd_pins {

					mux {
						groups = "GPIOC_0\0GPIOC_1\0GPIOC_2\0GPIOC_3\0GPIOC_4\0GPIOC_5";
						function = "gpio_periphs";
						bias-pull-down;
						output-low;
					};
				};

				sd_1bit_pins {
					phandle = <0x49>;

					mux {
						groups = "sdcard_d0\0sdcard_cmd";
						function = "sdcard";
						bias-pull-up;
						drive-strength-microamp = <0xfa0>;
					};

					mux1 {
						groups = "sdcard_clk";
						function = "sdcard";
						bias-pull-up;
						drive-strength-microamp = <0xfa0>;
					};
				};

				sd_clr_all_pins {

					mux {
						groups = "GPIOC_0\0GPIOC_1\0GPIOC_2\0GPIOC_3\0GPIOC_5";
						function = "gpio_periphs";
						output-high;
					};

					mux1 {
						groups = "GPIOC_4";
						function = "gpio_periphs";
						output-low;
					};
				};

				sd_clr_noall_pins {

					mux {
						groups = "GPIOC_0\0GPIOC_1\0GPIOC_4\0GPIOC_5";
						function = "gpio_periphs";
						output-high;
					};
				};

				ao_to_sd_uart_pins {

					mux {
						groups = "uart_ao_tx_a_c3\0uart_ao_rx_a_c2";
						function = "uart_ao_a_ee";
						bias-pull-up;
						input-enable;
					};
				};

				sd_iso7816_pins {

					mux {
						groups = "iso7816_clk_z\0iso7816_data_z";
						function = "iso7816";
						input-enable;
						bias-pull-down;
					};
				};

				sdio {
					phandle = <0x4b>;

					mux {
						groups = "sdio_d0\0sdio_d1\0sdio_d2\0sdio_d3\0sdio_clk\0sdio_cmd";
						function = "sdio";
						bias-pull-up;
						drive-strength-microamp = <0xbb8>;
					};
				};

				sdio_clk_gate {
					phandle = <0x4c>;

					mux {
						groups = "GPIOX_4";
						function = "gpio_periphs";
						bias-pull-down;
						drive-strength-microamp = <0xbb8>;
					};
				};

				hdmitx_hpd {
					phandle = <0x58>;

					mux {
						groups = "hdmitx_hpd_in";
						function = "hdmitx";
						bias-disable;
					};
				};

				hdmitx_hpd_gpio {

					mux {
						groups = "GPIOW_15";
						function = "gpio_periphs";
						bias-disable;
					};
				};

				hdmitx_ddc {
					phandle = <0x59>;

					mux {
						groups = "hdmitx_sda_w13\0hdmitx_sck_w14";
						function = "hdmitx";
						bias-disable;
						drive-strength-microamp = <0xbb8>;
					};
				};

				hdmirx_a_mux {
					phandle = <0xa4>;

					mux {
						groups = "hdmirx_a_hpd\0hdmirx_a_det\0hdmirx_a_sda\0hdmirx_a_sck";
						function = "hdmirx_a";
					};
				};

				hdmirx_b_mux {
					phandle = <0xa5>;

					mux {
						groups = "hdmirx_b_hpd\0hdmirx_b_det\0hdmirx_b_sda\0hdmirx_b_sck";
						function = "hdmirx_b";
					};
				};

				hdmirx_c_mux {
					phandle = <0xa6>;

					mux {
						groups = "hdmirx_c_hpd\0hdmirx_c_det\0hdmirx_c_sda\0hdmirx_c_sck";
						function = "hdmirx_c";
					};
				};

				cec_a {
					phandle = <0x5a>;

					mux {
						groups = "cec_a";
						function = "cec_a";
					};
				};

				cec_b {

					mux {
						groups = "cec_b";
						function = "cec_b";
					};
				};

				jtag_a_pin {
					phandle = <0x25>;

					mux {
						groups = "jtag_a_tdi\0jtag_a_tdo\0jtag_a_clk\0jtag_a_tms";
						function = "jtag_a";
					};
				};

				jtag_b_pin {
					phandle = <0x26>;

					mux {
						groups = "jtag_b_tdi\0jtag_b_tdo\0jtag_b_clk\0jtag_b_tms";
						function = "jtag_b";
					};
				};

				pwm_a_pins {
					phandle = <0x2f>;

					mux {
						groups = "pwm_a";
						function = "pwm_a";
						drive-strength-microamp = <0x1f4>;
					};
				};

				pwm_b_pins {

					mux {
						groups = "pwm_b";
						function = "pwm_b";
					};
				};

				pwm_c_pins {

					mux {
						groups = "pwm_c";
						function = "pwm_c";
					};
				};

				pwm_d_pins {

					mux {
						groups = "pwm_d";
						function = "pwm_d";
					};
				};

				pwm_e_pins {
					phandle = <0x83>;

					mux {
						groups = "pwm_e";
						function = "pwm_e";
					};
				};

				pwm_f_pins {
					phandle = <0x89>;

					mux {
						groups = "pwm_f";
						function = "pwm_f";
					};
				};

				pwm_ao_a_pins {

					mux {
						groups = "pwm_ao_a";
						function = "pwm_ao_a";
					};
				};

				pwm_ao_b_pins {

					mux {
						groups = "pwm_ao_b";
						function = "pwm_ao_b";
					};
				};

				pwm_ao_c_pins1 {

					mux {
						groups = "pwm_ao_c_d";
						function = "pwm_ao_c";
					};
				};

				pwm_ao_c_pins2 {

					mux {
						groups = "pwm_ao_c_e";
						function = "pwm_ao_c";
					};
				};

				pwm_ao_c_hiz_pins {

					mux {
						groups = "pwm_ao_c_hiz";
						function = "pwm_ao_c";
					};
				};

				pwm_ao_d_pins {
					phandle = <0x30>;

					mux {
						groups = "pwm_ao_d";
						function = "pwm_ao_d";
					};
				};

				pwm_ao_e_pins {

					mux {
						groups = "pwm_ao_e";
						function = "pwm_ao_e";
					};
				};

				pwm_ao_f_pins {

					mux {
						groups = "pwm_ao_f";
						function = "pwm_ao_f";
					};
				};

				pwm_ao_g_pins1 {

					mux {
						groups = "pwm_ao_g_d11";
						function = "pwm_ao_g";
					};
				};

				pwm_ao_g_pins2 {

					mux {
						groups = "pwm_ao_g_d7";
						function = "pwm_ao_g";
					};
				};

				pwm_ao_g_pins3 {

					mux {
						groups = "pwm_ao_g_e";
						function = "pwm_ao_g";
					};
				};

				pwm_ao_g_hiz_pins {

					mux {
						groups = "pwm_ao_g_hiz";
						function = "pwm_ao_g";
					};
				};

				pwm_ao_h_pins1 {
					phandle = <0x80>;

					mux {
						groups = "pwm_ao_h_d5";
						function = "pwm_ao_h";
					};
				};

				pwm_ao_d_pins2 {

					mux {
						groups = "pwm_ao_h_d10";
						function = "pwm_ao_h";
					};
				};

				remote_pin {
					phandle = <0x5b>;

					mux {
						groups = "remote_in";
						function = "remote_in";
						bias-disable;
					};
				};

				spifc_all_pins {
					phandle = <0x2e>;

					mux {
						groups = "nor_hold\0nor_d\0nor_q\0nor_c\0nor_wp\0nor_cs";
						function = "nor";
						drive-strength-microamp = <0xbb8>;
					};
				};

				spicc0_pins {

					mux {
						groups = "spi0_mosi\0spi0_miso\0spi0_sclk";
						function = "spi0";
						drive-strength-microamp = <0x7d0>;
					};
				};

				spicc1_pins_1 {

					mux {
						groups = "spi1_mosi_c\0spi1_miso_c\0spi1_sclk_c";
						function = "spi1";
						drive-strength-microamp = <0x7d0>;
					};
				};

				spicc1_pins_2 {

					mux {
						groups = "spi1_mosi_m\0spi1_miso_m\0spi1_sclk_m";
						function = "spi1";
						drive-strength-microamp = <0x7d0>;
					};
				};

				spicc2_pins {

					mux {
						groups = "spi2_mosi\0spi2_miso\0spi2_sclk";
						function = "spi2";
						drive-strength-microamp = <0x7d0>;
					};
				};

				spicc3_pins {
					phandle = <0x2c>;

					mux {
						groups = "spi3_mosi\0spi3_miso\0spi3_sclk";
						function = "spi3";
						drive-strength-microamp = <0x7d0>;
					};
				};

				spicc4_pins {

					mux {
						groups = "spi4_mosi\0spi4_miso\0spi4_sclk";
						function = "spi4";
						drive-strength-microamp = <0x7d0>;
					};
				};

				spicc5_pins {

					mux {
						groups = "spi5_mosi\0spi5_miso\0spi5_sclk";
						function = "spi5";
						drive-strength-microamp = <0x7d0>;
					};
				};

				irblaster_pin1 {

					mux {
						groups = "remote_out_d4";
						function = "remote_out";
					};
				};

				irblaster_pin2 {
					phandle = <0x61>;

					mux {
						groups = "remote_out_d6";
						function = "remote_out";
					};
				};

				spdifout_d {
					phandle = <0x43>;

					mux {
						groups = "spdif_out_d";
						function = "spdif_out";
					};
				};

				spdifout_d_mute {
					phandle = <0x44>;

					mux {
						groups = "GPIOD_8";
						function = "gpio_periphs";
						output-low;
					};
				};

				spdifout_t {

					mux {
						groups = "spdif_out_t";
						function = "spdif_out";
					};
				};

				spdifout_t_mute {

					mux {
						groups = "GPIOT_3";
						function = "gpio_periphs";
						output-low;
					};
				};

				spdifin_d {

					mux {
						groups = "spdif_in_d";
						function = "spdif_in";
					};
				};

				spdifin_t {

					mux {
						groups = "spdif_in_t";
						function = "spdif_in";
					};
				};

				mclk_1_pin {
					phandle = <0x3d>;

					mux {
						groups = "mclk1";
						function = "mclk";
					};
				};

				mclk_2_pin {

					mux {
						groups = "mclk2";
						function = "mclk";
					};
				};

				lcd_vbyone_a_pin {
					phandle = <0x7c>;

					mux {
						groups = "vx1_a_htpdn\0vx1_a_lockn";
						function = "vx1_a";
					};
				};

				lcd_vbyone_b_pin {
					phandle = <0x85>;

					mux {
						groups = "vx1_b_htpdn\0vx1_b_lockn";
						function = "vx1_b";
					};
				};

				lcd_edp_a_pin {
					phandle = <0x7e>;

					mux {
						groups = "edp_a_hpd";
						function = "edp_a";
					};
				};

				lcd_edp_b_pin {
					phandle = <0x87>;

					mux {
						groups = "edp_b_hpd";
						function = "edp_b";
					};
				};

				eth {

					mux {
						groups = "eth_mdio\0eth_mdc\0eth_rgmii_rx_clk\0eth_rx_dv\0eth_rxd0\0eth_rxd1\0eth_txen\0eth_txd0\0eth_txd1";
						function = "eth";
						drive-strength-microamp = <0xfa0>;
						bias-disable;
					};
				};

				eth-rgmii {

					mux {
						groups = "eth_rxd2_rgmii\0eth_rxd3_rgmii\0eth_rgmii_tx_clk\0eth_txd2_rgmii\0eth_txd3_rgmii";
						function = "eth";
						drive-strength-microamp = <0xfa0>;
						bias-disable;
					};
				};

				pdmin_pin {
					phandle = <0x42>;

					mux {
						groups = "pdm_dclk\0pdm_din0\0pdm_din1_m5\0pdm_din2\0pdm_din3";
						function = "pdm";
					};
				};

				tdm_a_pin {
					phandle = <0x3e>;

					mux {
						groups = "tdm_sclk1\0tdm_fs1\0tdm_d4\0tdm_d5";
						function = "tdm";
					};
				};

				lcd_vbyone_a_off_pin {
					phandle = <0x7d>;

					mux {
						groups = "GPIOY_10\0GPIOY_12";
						function = "gpio_periphs";
						input-enable;
					};
				};

				lcd_vbyone_b_off_pin {
					phandle = <0x86>;

					mux {
						groups = "GPIOY_11\0GPIOY_13";
						function = "gpio_periphs";
						input-enable;
					};
				};

				lcd_edp_a_off_pin {
					phandle = <0x7f>;

					mux {
						groups = "GPIOY_10";
						function = "gpio_periphs";
						input-enable;
					};
				};

				lcd_edp_b_off_pin {
					phandle = <0x88>;

					mux {
						groups = "GPIOY_11";
						function = "gpio_periphs";
						input-enable;
					};
				};

				bl_pwm_vs_on_pin {
					phandle = <0x84>;

					mux {
						groups = "pwm_vs_y";
						function = "pwm_vs";
					};
				};

				bl_pwm_off_pin {
					phandle = <0x81>;

					mux {
						groups = "GPIOY_1";
						function = "gpio_periphs";
						output-low;
					};
				};

				bl1_pwm_off_pin {
					phandle = <0x8a>;

					mux {
						groups = "GPIOY_8";
						function = "gpio_periphs";
						output-low;
					};
				};
			};

			interrupt-controller@4080 {
				compatible = "amlogic,meson-t7-gpio-intc\0amlogic,meson-gpio-intc";
				reg = <0x00 0x4080 0x00 0x20>;
				interrupt-controller;
				#interrupt-cells = <0x02>;
				amlogic,channel-interrupts = <0x0a 0x0b 0x0c 0x0d 0x0e 0x0f 0x10 0x11 0x12 0x13 0x14 0x15>;
				phandle = <0x34>;
			};

			spi@50000 {
				compatible = "amlogic,meson-g12-spicc";
				reg = <0x00 0x50000 0x00 0x44>;
				interrupts = <0x00 0xb7 0x04>;
				clocks = <0x0d 0x196 0x0d 0x109>;
				clock-names = "core\0async";
				#address-cells = <0x01>;
				#size-cells = <0x00>;
				power-domains = <0x0c 0x2a>;
				status = "disabled";
			};

			spi@52000 {
				compatible = "amlogic,meson-g12-spicc";
				reg = <0x00 0x52000 0x00 0x44>;
				interrupts = <0x00 0xb8 0x04>;
				clocks = <0x0d 0x197 0x0d 0x10c>;
				clock-names = "core\0async";
				#address-cells = <0x01>;
				#size-cells = <0x00>;
				power-domains = <0x0c 0x2b>;
				status = "disabled";
			};

			spi@54000 {
				compatible = "amlogic,meson-g12-spicc";
				reg = <0x00 0x54000 0x00 0x44>;
				interrupts = <0x00 0xa7 0x04>;
				clocks = <0x0d 0x1c1 0x0d 0x10f>;
				clock-names = "core\0async";
				#address-cells = <0x01>;
				#size-cells = <0x00>;
				power-domains = <0x0c 0x2c>;
				status = "disabled";
			};

			spi@4a000 {
				compatible = "amlogic,meson-g12-spicc";
				reg = <0x00 0x4a000 0x00 0x44>;
				interrupts = <0x00 0xbd 0x04>;
				clocks = <0x0d 0x1c2 0x0d 0x112>;
				clock-names = "core\0async";
				assigned-clocks = <0x0d 0x10c>;
				assigned-clock-parents = <0x0d 0x05>;
				assigned-clock-rates = <0xbebc200>;
				parent_clk_fixed;
				#address-cells = <0x01>;
				#size-cells = <0x00>;
				power-domains = <0x0c 0x2d>;
				status = "disabled";
				pinctrl-names = "default";
				pinctrl-0 = <0x2c>;
				cs-gpios = <0x2d 0x64 0x00>;

				spi-nor@0 {
					compatible = "jedec,spi-nor";
					status = "okay";
					reg = <0x00>;
					spi-max-frequency = <0xf42400>;
				};
			};

			spi@4c000 {
				compatible = "amlogic,meson-g12-spicc";
				reg = <0x00 0x4c000 0x00 0x44>;
				interrupts = <0x00 0xbe 0x04>;
				clocks = <0x0d 0x1c3 0x0d 0x115>;
				clock-names = "core\0async";
				#address-cells = <0x01>;
				#size-cells = <0x00>;
				power-domains = <0x0c 0x2e>;
				status = "disabled";
			};

			spi@4e000 {
				compatible = "amlogic,meson-g12-spicc";
				reg = <0x00 0x4e000 0x00 0x44>;
				interrupts = <0x00 0xbf 0x04>;
				clocks = <0x0d 0x1c4 0x0d 0x118>;
				clock-names = "core\0async";
				#address-cells = <0x01>;
				#size-cells = <0x00>;
				power-domains = <0x0c 0x2f>;
				status = "disabled";
			};

			spi@56000 {
				compatible = "amlogic,meson-spifc";
				status = "disabled";
				reg = <0x00 0x56000 0x00 0x80>;
				clock-names = "default";
				clocks = <0x0d 0x188>;
				pinctrl-names = "default";
				pinctrl-0 = <0x2e>;
				#address-cells = <0x01>;
				#size-cells = <0x00>;

				spi-nor@0 {
					compatible = "jedec,spi-nor";
					status = "disabled";
					reg = <0x00>;
					spi-max-frequency = <0xf42400>;
				};
			};

			pwm@58000 {
				compatible = "amlogic,meson-v2-pwm";
				reg = <0x00 0x58000 0x00 0x24>;
				#pwm-cells = <0x03>;
				clocks = <0x0d 0xdf 0x0d 0xe2>;
				clock-names = "clkin0\0clkin1";
				status = "okay";
				pinctrl-0 = <0x2f>;
				pinctrl-names = "default";
			};

			pwm@5a000 {
				compatible = "amlogic,meson-v2-pwm";
				reg = <0x00 0x5a000 0x00 0x24>;
				#pwm-cells = <0x03>;
				clocks = <0x0d 0xe5 0x0d 0xe8>;
				clock-names = "clkin0\0clkin1";
				status = "disabled";
			};

			pwm@5c000 {
				compatible = "amlogic,meson-v2-pwm";
				reg = <0x00 0x5c000 0x00 0x24>;
				#pwm-cells = <0x03>;
				clocks = <0x0d 0xeb 0x0d 0xee>;
				clock-names = "clkin0\0clkin1";
				status = "okay";
			};

			pwm@5e000 {
				compatible = "amlogic,meson-v2-pwm";
				reg = <0x00 0x5e000 0x00 0x24>;
				#pwm-cells = <0x03>;
				clocks = <0x0d 0xf1 0x0d 0xf4>;
				clock-names = "clkin0\0clkin1";
				status = "disabled";
				phandle = <0x29>;
			};

			pwm@60000 {
				compatible = "amlogic,meson-v2-pwm";
				reg = <0x00 0x60000 0x00 0x24>;
				#pwm-cells = <0x03>;
				clocks = <0x0d 0xf7 0x0d 0xfa>;
				clock-names = "clkin0\0clkin1";
				status = "okay";
				pinctrl-names = "default";
				pinctrl-0 = <0x30>;
				phandle = <0x28>;
			};

			pwm@30000 {
				compatible = "amlogic,meson-v2-pwm";
				reg = <0x00 0x30000 0x00 0x24>;
				#pwm-cells = <0x03>;
				clocks = <0x0d 0xfd 0x0d 0x100>;
				clock-names = "clkin0\0clkin1";
				status = "disabled";
			};

			pwm@32000 {
				compatible = "amlogic,meson-v2-pwm";
				reg = <0x00 0x32000 0x00 0x24>;
				#pwm-cells = <0x03>;
				clocks = <0x0d 0x103 0x0d 0x106>;
				clock-names = "clkin0\0clkin1";
				status = "disabled";
				phandle = <0x8b>;
			};

			i2c@66000 {
				compatible = "amlogic,meson-i2c";
				reg = <0x00 0x66000 0x00 0x48>;
				interrupts = <0x00 0xa0 0x01>;
				#address-cells = <0x01>;
				#size-cells = <0x00>;
				clocks = <0x0d 0x19b>;
				status = "disabled";
			};

			i2c@68000 {
				compatible = "amlogic,meson-i2c";
				reg = <0x00 0x68000 0x00 0x48>;
				interrupts = <0x00 0xa1 0x01>;
				#address-cells = <0x01>;
				#size-cells = <0x00>;
				clocks = <0x0d 0x19c>;
				status = "okay";
				pinctrl-names = "default";
				pinctrl-0 = <0x31>;

				tas5707_36@1b {
					compatible = "ti,tas5707";
					#sound-dai-cells = <0x00>;
					reg = <0x1b>;
					status = "okay";
					reset_pin = <0x2d 0x6e 0x00>;
					phandle = <0xa8>;
				};

				tas5707_3a@1d {
					compatible = "ti,tas5707";
					#sound-dai-cells = <0x00>;
					reg = <0x1d>;
					status = "okay";
					phandle = <0xa9>;
				};
			};

			i2c@6a000 {
				compatible = "amlogic,meson-i2c";
				reg = <0x00 0x6a000 0x00 0x48>;
				interrupts = <0x00 0xa2 0x01>;
				#address-cells = <0x01>;
				#size-cells = <0x00>;
				clocks = <0x0d 0x19d>;
				status = "disabled";
			};

			i2c@6c000 {
				compatible = "amlogic,meson-i2c";
				reg = <0x00 0x6c000 0x00 0x48>;
				interrupts = <0x00 0xa3 0x01>;
				#address-cells = <0x01>;
				#size-cells = <0x00>;
				clocks = <0x0d 0x19e>;
				status = "disabled";
			};

			i2c@6e000 {
				compatible = "amlogic,meson-i2c";
				reg = <0x00 0x6e000 0x00 0x48>;
				interrupts = <0x00 0xa4 0x01>;
				#address-cells = <0x01>;
				#size-cells = <0x00>;
				clocks = <0x0d 0x19f>;
				status = "disabled";
			};

			i2c@70000 {
				compatible = "amlogic,meson-i2c";
				reg = <0x00 0x70000 0x00 0x48>;
				interrupts = <0x00 0xa5 0x01>;
				#address-cells = <0x01>;
				#size-cells = <0x00>;
				clocks = <0x0d 0x1a0>;
				status = "disabled";
			};

			i2c@76000 {
				compatible = "amlogic,meson-i2c";
				reg = <0x00 0x76000 0x00 0x48>;
				interrupts = <0x00 0x14a 0x01>;
				#address-cells = <0x01>;
				#size-cells = <0x00>;
				clocks = <0x0d 0x1c5>;
				status = "okay";
				clock-frequency = <0x61a80>;
				pinctrl-names = "default";
				pinctrl-0 = <0x32>;

				pmic@4b {
					compatible = "rohm,bd71837";
					reg = <0x4b>;
					clocks = <0x33>;
					clock-names = "osc";
					clock-output-names = "pmic_clk";
					interrupt-parent = <0x34>;
					interrupts = <0x4b 0x01>;
					interrupt-names = "irq";
					rohm,reset-snvs-powered;

					regulators {

						BUCK1 {
							regulator-name = "VDD_NPU";
							regulator-min-microvolt = <0xaae60>;
							regulator-max-microvolt = <0x13d620>;
							regulator-boot-on;
							regulator-ramp-delay = <0x4e2>;
							rohm,dvs-run-voltage = <0xdbba0>;
							rohm,dvs-idle-voltage = <0xcf850>;
							rohm,dvs-suspend-voltage = "\0\f5";
							regulator-always-on;
						};

						BUCK2 {
							regulator-name = "VDD_EE";
							regulator-min-microvolt = <0xaae60>;
							regulator-max-microvolt = <0x13d620>;
							regulator-boot-on;
							regulator-ramp-delay = <0x4e2>;
							rohm,dvs-run-voltage = <0xcd140>;
							rohm,dvs-idle-voltage = <0xdbba0>;
							regulator-always-on;
						};

						BUCK3 {
							regulator-name = "VDD_CPU_B";
							regulator-min-microvolt = <0xaae60>;
							regulator-max-microvolt = <0x13d620>;
							regulator-boot-on;
							rohm,dvs-run-voltage = <0xf4240>;
							regulator-always-on;
							phandle = <0x1d>;
						};

						BUCK4 {
							regulator-name = "VDD_DDR";
							regulator-min-microvolt = <0xaae60>;
							regulator-max-microvolt = <0x13d620>;
							rohm,dvs-run-voltage = <0xf4240>;
							regulator-always-on;
						};

						BUCK5 {
							regulator-name = "VDDQ";
							regulator-min-microvolt = <0xaae60>;
							regulator-max-microvolt = <0x149970>;
							regulator-boot-on;
							regulator-always-on;
						};

						BUCK6 {
							regulator-name = "VDDIO_3V3";
							regulator-min-microvolt = <0x2dc6c0>;
							regulator-max-microvolt = <0x325aa0>;
							regulator-boot-on;
							regulator-always-on;
						};

						BUCK7 {
							regulator-name = "VDDIO_1V8";
							regulator-min-microvolt = <0x187d88>;
							regulator-max-microvolt = <0x1e70f8>;
							regulator-boot-on;
							regulator-always-on;
						};

						BUCK8 {
							regulator-name = "VDD_GPU";
							regulator-min-microvolt = "\0\f5";
							regulator-max-microvolt = <0x155cc0>;
							regulator-boot-on;
							regulator-always-on;
						};

						LDO1 {
							regulator-name = "VDD_CPU_A";
							regulator-min-microvolt = <0x186a00>;
							regulator-max-microvolt = <0x1cfde0>;
							regulator-boot-on;
							regulator-always-on;
						};

						LDO2 {
							regulator-name = "ldo2";
							regulator-min-microvolt = <0xdbba0>;
							regulator-max-microvolt = <0xdbba0>;
						};

						LDO3 {
							regulator-name = "VDDAO_1V8";
							regulator-min-microvolt = <0x1b7740>;
							regulator-max-microvolt = <0x325aa0>;
							regulator-boot-on;
							regulator-always-on;
						};

						LDO4 {
							regulator-name = "CAMERA_VDD";
							regulator-min-microvolt = <0xdbba0>;
							regulator-max-microvolt = <0x1b7740>;
						};

						LDO5 {
							regulator-name = "WIFI_BT_VIO";
							regulator-min-microvolt = <0x1b7740>;
							regulator-max-microvolt = <0x325aa0>;
						};

						LDO6 {
							regulator-name = "BUCK8_EXT";
							regulator-min-microvolt = <0xdbba0>;
							regulator-max-microvolt = <0x1b7740>;
							regulator-boot-on;
							regulator-always-on;
						};

						LDO7 {
							regulator-name = "TOUCH_AVDD";
							regulator-min-microvolt = <0x1b7740>;
							regulator-max-microvolt = <0x325aa0>;
						};

						MUXSW_EN {
							regulator-name = "BACKLIGHT";
							regulator-min-microvolt = <0x1b7740>;
							regulator-max-microvolt = <0x1b7740>;
							regulator-always-on;
						};
					};
				};
			};

			i2c@86000 {
				compatible = "amlogic,meson-i2c";
				reg = <0x00 0x86000 0x00 0x48>;
				interrupts = <0x00 0x14b 0x01>;
				#address-cells = <0x01>;
				#size-cells = <0x00>;
				clocks = <0x0d 0x1c6>;
				status = "disabled";
			};

			serial@7a000 {
				compatible = "amlogic,meson-uart";
				reg = <0x00 0x7a000 0x00 0x18>;
				interrupts = <0x00 0xa9 0x01>;
				status = "disabled";
				clocks = <0x2a 0x0d 0x18e>;
				clock-names = "clk_uart\0clk_gate";
				xtal_tick_en = <0x02>;
				fifosize = <0x40>;
				pinctrl-names = "default";
				pinctrl-0 = <0x35>;
				support-sysrq = <0x01>;
			};

			mdio-multiplexer@28000 {
				compatible = "amlogic,g12a-mdio-mux";
				reg = <0x00 0x28000 0x00 0xa4>;
				clocks = <0x0d 0x17e 0x2a 0x0d 0x2a>;
				clock-names = "pclk\0clkin0\0clkin1";
				mdio-parent-bus = <0x36>;
				#address-cells = <0x01>;
				#size-cells = <0x00>;
				enet_type = <0x05>;
				tx_amp_src = <0xfe010330>;

				mdio@0 {
					reg = <0x00>;
					#address-cells = <0x01>;
					#size-cells = <0x00>;
				};

				mdio@1 {
					reg = <0x01>;
					#address-cells = <0x01>;
					#size-cells = <0x00>;

					ethernet_phy@8 {
						compatible = "ethernet-phy-id0180.3301\0ethernet-phy-ieee802.3-c22";
						interrupts = <0x00 0x154 0x04>;
						reg = <0x08>;
						max-speed = <0x64>;
						phandle = <0x4d>;
					};
				};
			};

			reset-controller@2000 {
				compatible = "amlogic,meson-t7-reset";
				reg = <0x00 0x2000 0x00 0x98>;
				#reset-cells = <0x01>;
				phandle = <0x3b>;
			};

			cpu_version {
				compatible = "amlogic,meson-gx-ao-secure\0syscon";
				reg = <0x00 0x10220 0x00 0x140>;
				amlogic,has-chip-id;
			};
		};

		crgphy20@fe03c000 {
			compatible = "amlogic, amlogic-crg-drd-usb2";
			status = "okay";
			#phy-cells = <0x00>;
			reg = <0x00 0xfe03a000 0x00 0x80 0x00 0xfe002000 0x00 0x100 0x00 0xfe03c000 0x00 0x2000>;
			pll-setting-1 = <0x9400414>;
			pll-setting-2 = <0x927e0000>;
			pll-setting-3 = <0xac5f69e5>;
			pll-setting-4 = <0xbe18>;
			pll-setting-5 = <0x8000fff>;
			pll-setting-6 = <0x78000>;
			pll-setting-7 = <0xe0004>;
			pll-setting-8 = <0xe000c>;
			dis-thred-enhance = <0x02>;
			version = <0x02>;
			phy0-reset-level-bit = <0x08>;
			usb-reset-bit = <0x04>;
			reset-level = <0x40>;
			pwr-ctl = <0x00>;
			clocks = <0x0d 0x199>;
			clock-names = "crg_general";
			phy-id = <0x00>;
			portnum = <0x01>;
			gpio-vbus-power = "GPIOM_8";
			gpios = <0x2d 0x7b 0x00>;
			phandle = <0x39>;
		};

		crgphy21@fe03e000 {
			compatible = "amlogic, amlogic-crg-drd-usb2";
			status = "okay";
			#phy-cells = <0x00>;
			reg = <0x00 0xfe03a020 0x00 0x60 0x00 0xfe002000 0x00 0x100 0x00 0xfe03e000 0x00 0x2000>;
			pll-setting-1 = <0x9400414>;
			pll-setting-2 = <0x927e0000>;
			pll-setting-3 = <0xac5f69e5>;
			pll-setting-4 = <0xbe18>;
			pll-setting-5 = <0x8000fff>;
			pll-setting-6 = <0x78000>;
			pll-setting-7 = <0xe0004>;
			pll-setting-8 = <0xe000c>;
			dis-thred-enhance = <0x02>;
			version = <0x02>;
			phy0-reset-level-bit = <0x09>;
			usb-reset-bit = <0x04>;
			reset-level = <0x40>;
			pwr-ctl = <0x00>;
			clocks = <0x0d 0x199>;
			clock-names = "crg_general";
			phy-id = <0x01>;
			portnum = <0x01>;
			gpio-vbus-power = "GPIOM_9";
			gpios = <0x2d 0x7c 0x00>;
			phandle = <0x37>;
		};

		crg3phy21@fe03a080 {
			compatible = "amlogic, amlogic-crg-drd-usb3";
			status = "okay";
			#phy-cells = <0x00>;
			reg = <0x00 0xfe03a080 0x00 0x20>;
			phy1-reg = <0xfe062000>;
			phy1-reg-size = <0x2000>;
			phy-pcie-reg = <0xfe02a000>;
			phy-pcie-reg-size = <0x2000>;
			reset-reg = <0xfe002000>;
			reset-reg-size = <0x100>;
			reset-level = <0x40>;
			usb3-apb-reset-bit = <0x17>;
			usb3-phy-reset-bit = <0x16>;
			usb3-reset-shit = <0x04>;
			clocks = <0x0d 0x25 0x0d 0x35>;
			clock-names = "pcie_refpll\0pcie_hcsl";
			phy-id = <0x01>;
			portnum = <0x00>;
			phandle = <0x38>;
		};

		crg3phy20@fe03a080 {
			compatible = "amlogic, amlogic-crg-drd-usb3";
			status = "okay";
			#phy-cells = <0x00>;
			reg = <0x00 0xfe03a080 0x00 0x20>;
			phy1-reg = <0xfe062000>;
			phy1-reg-size = <0x2000>;
			phy-pcie-reg = <0xfe02a000>;
			phy-pcie-reg-size = <0x2000>;
			reset-reg = <0xfe002000>;
			reset-reg-size = <0x100>;
			reset-level = <0x40>;
			usb3-apb-reset-bit = <0x17>;
			usb3-phy-reset-bit = <0x16>;
			usb3-reset-shit = <0x04>;
			clocks = <0x0d 0x25 0x0d 0x35>;
			clock-names = "pcie_refpll\0pcie_hcsl";
			phy-id = <0x00>;
			portnum = <0x01>;
			phandle = <0x3a>;
		};

		crg20otg@fe03a000 {
			compatible = "amlogic, amlogic-crg-otg";
			status = "disable";
			usb2-phy-reg = <0xfe03a000>;
			usb2-phy-reg-size = <0x80>;
			usb3-phy-reg = <0xfe03a080>;
			usb3-phy-reg-size = <0x20>;
			interrupts = <0x00 0x81 0x01>;
			controller-type = <0x03>;
		};

		crg21otg@fe03a020 {
			compatible = "amlogic, amlogic-crg-otg";
			status = "okay";
			usb2-phy-reg = <0xfe03a020>;
			usb2-phy-reg-size = <0x60>;
			usb3-phy-reg = <0xfe03a080>;
			usb3-phy-reg-size = <0x20>;
			interrupts = <0x00 0x119 0x01>;
			controller-type = <0x03>;
		};

		crg2drd@fdd00000 {
			status = "okay";
			reg = <0x00 0xfdd00000 0x00 0x100000>;
			interrupts = <0x00 0x83 0x01>;
			usb-phy = <0x37 0x38>;
			cpu-type = "gxl";
			clock-src = "usb3.0";
			clocks = <0x0d 0x199>;
			clock-names = "crg_general";
			compatible = "amlogic, crg-drd";
		};

		crg3drd@fde00000 {
			status = "okay";
			reg = <0x00 0xfde00000 0x00 0x100000>;
			interrupts = <0x00 0x82 0x01>;
			usb-phy = <0x39 0x3a>;
			cpu-type = "gxl";
			clock-src = "usb3.0";
			clocks = <0x0d 0x199>;
			clock-names = "crg_general";
			compatible = "amlogic, crg-host-drd";
		};

		crgudc3@0xfde00000 {
			compatible = "amlogic, crg_udc";
			status = "disable";
			device_name = "crg_udc_3";
			reg = <0x00 0xfde00000 0x00 0x100000>;
			interrupts = <0x00 0x82 0x01>;
			clock-src = "usb0";
			port-speed = <0x05>;
			phy-reg = <0xfe03a000>;
			phy-reg-size = <0xa0>;
			clocks = <0x0d 0x199>;
			clock-names = "usb_general";
			phy-id = <0x00>;
		};

		crgudc2@0xfdd00000 {
			compatible = "amlogic, crg_udc";
			status = "okay";
			device_name = "crg_udc_2";
			reg = <0x00 0xfdd00000 0x00 0x100000>;
			interrupts = <0x00 0x83 0x01>;
			clock-src = "usb0";
			port-speed = <0x03>;
			phy-reg = <0xfe03a020>;
			phy-reg-size = <0xa0>;
			clocks = <0x0d 0x199>;
			clock-names = "usb_general";
			phy-id = <0x01>;
		};

		dummy {
			#sound-dai-cells = <0x00>;
			compatible = "amlogic, aml_dummy_codec";
			status = "okay";
			phandle = <0xac>;
		};

		codec {
			#sound-dai-cells = <0x00>;
			compatible = "amlogic, tm2_revb_acodec";
			reg = <0x00 0xfe01a000 0x00 0x1c>;
			tdmout_index = <0x00>;
			tdmin_index = <0x00>;
			dat0_ch_sel = <0x01>;
			reset-names = "acodec";
			resets = <0x3b 0x58>;
			status = "okay";
			phandle = <0xaa>;
		};

		audio_data {
			compatible = "amlogic, audio_data";
			mem_in_base_cmd = <0x82000020>;
			query_licence_cmd = <0x82000050>;
			status = "okay";
		};

		amaudio {
			compatible = "amlogic, amaudio";
			reg = <0x00 0xfe440000 0x00 0x10000>;
			reg-names = "otp_tee_base";
			status = "okay";
		};

		audiobus@0xFE330000 {
			compatible = "amlogic, audio-controller\0simple-bus";
			reg = <0x00 0xfe330000 0x00 0x3000>;
			#address-cells = <0x02>;
			#size-cells = <0x02>;
			ranges = <0x00 0x00 0x00 0xfe330000 0x00 0x3000>;
			power-domains = <0x0c 0x33>;
			chip_id = <0x36>;
			status = "okay";

			audio_clocks {
				compatible = "amlogic, t7-audio-clocks";
				#clock-cells = <0x01>;
				reg = <0x00 0x00 0x00 0xb0>;
				status = "okay";
				phandle = <0x3c>;
			};

			ddr_manager {
				compatible = "amlogic, t5-audio-ddr-manager";
				interrupts = <0x00 0x20 0x01 0x00 0x21 0x01 0x00 0x22 0x01 0x00 0x2d 0x01 0x00 0x24 0x01 0x00 0x25 0x01 0x00 0x26 0x01 0x00 0x2e 0x01>;
				interrupt-names = "toddr_a\0toddr_b\0toddr_c\0toddr_d\0frddr_a\0frddr_b\0frddr_c\0frddr_d";
				status = "okay";
			};

			pinctrl {
				compatible = "amlogic, audio-pinctrl";
				status = "okay";

				tdm_d4_pin {
					phandle = <0x3f>;

					mux {
						groups = "tdm_d4";
						function = "tdmouta_lane0";
					};
				};

				tdm_d5_pin {
					phandle = <0x40>;

					mux {
						groups = "tdm_d5";
						function = "tdmouta_lane1";
					};
				};

				tdm_clk_pin {
					phandle = <0x41>;

					mux {
						groups = "tdm_sclk1\0tdm_lrclk1";
						function = "tdm_clk_outa";
					};
				};
			};

			tdm@0 {
				compatible = "amlogic, t7-snd-tdma";
				#sound-dai-cells = <0x00>;
				dai-tdm-lane-slot-mask-in = <0x01 0x00>;
				dai-tdm-lane-slot-mask-out = <0x01 0x01 0x01 0x01>;
				dai-tdm-clk-sel = <0x00>;
				clocks = <0x3c 0x29 0x3c 0x40 0x0d 0x2d 0x0d 0x2f 0x3c 0x30>;
				clock-names = "mclk\0mclk_pad\0clk_srcpll\0samesource_srcpll\0samesource_clk";
				pinctrl-names = "tdm_pins";
				pinctrl-0 = <0x3d 0x3e 0x3f 0x40 0x41>;
				samesource_sel = <0x03>;
				acodec_adc = <0x01>;
				start_clk_enable = <0x01>;
				clk_tuning_enable = <0x01>;
				status = "okay";
				phandle = <0xa7>;

				Channel_Mask {
					Spdif_samesource_Channel_Mask = "i2s_2/3";
				};
			};

			tdm@1 {
				compatible = "amlogic, t7-snd-tdmb";
				#sound-dai-cells = <0x00>;
				dai-tdm-lane-slot-mask-in = <0x01 0x00 0x00 0x00>;
				dai-tdm-lane-slot-mask-out = <0x00 0x01 0x00 0x00>;
				dai-tdm-clk-sel = <0x01>;
				clocks = <0x3c 0x2a 0x0d 0x2f>;
				clock-names = "mclk\0clk_srcpll";
				status = "okay";
				phandle = <0xab>;
			};

			tdm@2 {
				compatible = "amlogic, t7-snd-tdmc";
				#sound-dai-cells = <0x00>;
				dai-tdm-lane-slot-mask-in = <0x01 0x00 0x00 0x00>;
				dai-tdm-lane-slot-mask-out = <0x01 0x00 0x00 0x00>;
				dai-tdm-clk-sel = <0x02>;
				clocks = <0x3c 0x2b 0x0d 0x31>;
				clock-names = "mclk\0clk_srcpll";
				status = "okay";
				phandle = <0xad>;
			};

			pdm {
				compatible = "amlogic, tm2-snd-pdm";
				#sound-dai-cells = <0x00>;
				clocks = <0x3c 0x01 0x0d 0x07 0x0d 0x33 0x3c 0x34 0x3c 0x35>;
				clock-names = "gate\0sysclk_srcpll\0dclk_srcpll\0pdm_dclk\0pdm_sysclk";
				pinctrl-names = "pdm_pins";
				pinctrl-0 = <0x42>;
				filter_mode = <0x01>;
				train_sample_count = <0x0b>;
				status = "okay";
				phandle = <0xae>;
			};

			spdif@0 {
				compatible = "amlogic, tm2-revb-snd-spdif-a";
				#sound-dai-cells = <0x00>;
				clocks = <0x0d 0x2d 0x0d 0x09 0x3c 0x10 0x3c 0x11 0x3c 0x2f 0x3c 0x30>;
				clock-names = "sysclk\0fixed_clk\0gate_spdifin\0gate_spdifout\0clk_spdifin\0clk_spdifout";
				interrupts = <0x00 0x23 0x01>;
				interrupt-names = "irq_spdifin";
				pinctrl-names = "spdif_pins\0spdif_pins_mute";
				pinctrl-0 = <0x43>;
				pinctrl-1 = <0x44>;
				samesource_sel = <0x04>;
				clk_tuning_enable = <0x01>;
				status = "okay";
				phandle = <0xaf>;
			};

			spdif@1 {
				compatible = "amlogic, tm2-revb-snd-spdif-b";
				#sound-dai-cells = <0x00>;
				clocks = <0x0d 0x31 0x3c 0x15 0x3c 0x36>;
				clock-names = "sysclk\0gate_spdifout\0clk_spdifout";
				status = "okay";
				phandle = <0xb0>;
			};

			extn {
				compatible = "amlogic, t7-snd-extn";
				#sound-dai-cells = <0x00>;
				interrupts = <0x00 0x2a 0x01>;
				interrupt-names = "irq_frhdmirx";
				status = "okay";
				phandle = <0xb1>;
			};

			effect {
				compatible = "amlogic, snd-effect-v4";
				#sound-dai-cells = <0x00>;
				clocks = <0x3c 0x16 0x0d 0x0b 0x3c 0x39>;
				clock-names = "gate\0srcpll\0eqdrc";
				eqdrc_module = <0x00>;
				lane_mask = <0x01>;
				channel_mask = <0xff>;
				status = "okay";
			};

			resample@0 {
				compatible = "amlogic, t5-resample-a";
				clocks = <0x0d 0x2f 0x3c 0x2a 0x3c 0x31>;
				clock-names = "resample_pll\0resample_src\0resample_clk";
				resample_module = <0x08>;
				status = "okay";
			};

			resample@1 {
				compatible = "amlogic, t5-resample-b";
				clocks = <0x0d 0x33 0x3c 0x2e 0x3c 0x37>;
				clock-names = "resample_pll\0resample_src\0resample_clk";
				capture_sample_rate = <0x3e80>;
				status = "okay";
			};

			vad {
				compatible = "amlogic, snd-vad";
				#sound-dai-cells = <0x00>;
				clocks = <0x3c 0x1b 0x0d 0x0b 0x3c 0x3a>;
				clock-names = "gate\0pll\0clk";
				interrupts = <0x00 0x27 0x01 0x00 0x2c 0x01>;
				interrupt-names = "irq_wakeup\0irq_frame_sync";
				src = <0x04>;
				level = <0x01>;
				status = "okay";
			};

			loopback@0 {
				compatible = "amlogic, t5-loopbacka";
				#sound-dai-cells = <0x00>;
				clocks = <0x3c 0x01 0x0d 0x07 0x0d 0x33 0x3c 0x34 0x3c 0x35 0x0d 0x2d 0x3c 0x29>;
				clock-names = "pdm_gate\0pdm_sysclk_srcpll\0pdm_dclk_srcpll\0pdm_dclk\0pdm_sysclk\0tdminlb_mpll\0tdminlb_mclk";
				datain_src = <0x04>;
				datain_chnum = <0x04>;
				datain_chmask = <0x0f>;
				datain-lane-mask-in = <0x01 0x00 0x01 0x00>;
				mclk-fs = <0x100>;
				datalb_src = <0x00>;
				datalb_chnum = <0x02>;
				datalb_chmask = <0x03>;
				datalb-lane-mask-in = <0x01 0x00 0x00 0x00>;
				status = "okay";
				phandle = <0xb2>;
			};

			loopback@1 {
				compatible = "amlogic, t5-loopbackb";
				#sound-dai-cells = <0x00>;
				clocks = <0x3c 0x01 0x0d 0x07 0x0d 0x33 0x3c 0x34 0x3c 0x35 0x0d 0x2d 0x3c 0x29>;
				clock-names = "pdm_gate\0pdm_sysclk_srcpll\0pdm_dclk_srcpll\0pdm_dclk\0pdm_sysclk\0tdminlb_mpll\0tdminlb_mclk";
				mclk-fs = <0x100>;
				datain_src = <0x04>;
				datain_chnum = <0x04>;
				datain_chmask = <0x0f>;
				datain-lane-mask-in = <0x01 0x00 0x01 0x00>;
				datalb_src = <0x01>;
				datalb_chnum = <0x02>;
				datalb_chmask = <0x03>;
				datalb-lane-mask-in = <0x01 0x00 0x00 0x00>;
				status = "disabled";
			};
		};

		bus@fe333000 {
			compatible = "simple-bus";
			reg = <0x00 0xfe333000 0x00 0x1000>;
			#address-cells = <0x02>;
			#size-cells = <0x02>;
			ranges = <0x00 0x00 0x00 0xfe333000 0x00 0x1000>;

			earc@0 {
				compatible = "amlogic, t7-snd-earc";
				#sound-dai-cells = <0x00>;
				status = "disabled";
				reg = <0x00 0x800 0x00 0x400 0x00 0xc00 0x00 0x200 0x00 0xe00 0x00 0x200>;
				reg-names = "rx_cmdc\0rx_dmac\0rx_top";
				clocks = <0x3c 0x3d 0x3c 0x3e 0x0d 0x09 0x0d 0x09>;
				clock-names = "rx_cmdc\0rx_dmac\0rx_cmdc_srcpll\0rx_dmac_srcpll";
				interrupts = <0x00 0x30 0x04>;
				interrupt-names = "earc_rx";
			};
		};

		aml_snd_iomap {
			compatible = "amlogic, snd-iomap";
			status = "okay";
			#address-cells = <0x02>;
			#size-cells = <0x02>;
			ranges;

			pdm_bus {
				reg = <0x00 0xfe331000 0x00 0x400>;
			};

			audiobus_base {
				reg = <0x00 0xfe330000 0x00 0x1000>;
			};

			audiolocker_base {
				reg = <0x00 0xfe331400 0x00 0x400>;
			};

			eqdrc_base {
				reg = <0x00 0xfe332000 0x00 0x1000>;
			};

			vad_base {
				reg = <0x00 0xfe331800 0x00 0x400>;
			};

			resampleA_base {
				reg = <0x00 0xfe331c00 0x00 0x104>;
			};

			resampleB_base {
				reg = <0x00 0xfe334000 0x00 0x104>;
			};
		};

		hdmirx_arc {
			compatible = "amlogic, hdmirx-arc-iomap";
			reg = <0x00 0xfe39c000 0x00 0x10c>;
			#address-cells = <0x02>;
			#size-cells = <0x02>;
			reg-names = "hdmirx-arc";
		};

		pcie@f5000000 {
			compatible = "amlogic, amlogic-pcie-v2\0snps,dw-pcie";
			reg = <0x00 0xf5000000 0x00 0x400000 0x00 0xfe02c000 0x00 0x2000 0x00 0xf5400000 0x00 0x200000 0x00 0xfe02a000 0x00 0x2000 0x00 0xfe002044 0x00 0x10>;
			reg-names = "elbi\0cfg\0config\0phy\0reset";
			interrupts = <0x00 0x8d 0x01>;
			#interrupt-cells = <0x01>;
			bus-range = <0x00 0xff>;
			#address-cells = <0x03>;
			#size-cells = <0x02>;
			interrupt-map-mask = <0x00 0x00 0x00 0x00>;
			interrupt-map = <0x00 0x00 0x00 0x00 0x01 0x00 0x8f 0x01>;
			device_type = "pci";
			ranges = <0x81000000 0x00 0x00 0x00 0xf5600000 0x00 0x100000 0x82000000 0x00 0xf5700000 0x00 0xf5700000 0x00 0x1900000>;
			num-lanes = <0x01>;
			pcie-num = <0x01>;
			clocks = <0x0d 0x25 0x0d 0x198 0x0d 0x19a 0x0d 0x35>;
			clock-names = "pcie_refpll\0pcie\0pcie_phy\0pcie_hcsl";
			gpio-type = <0x02>;
			pcie-apb-rst-bit = <0x0e>;
			pcie-phy-rst-bit = <0x0d>;
			pcie-ctrl-a-rst-bit = <0x0c>;
			pwr-ctl = <0x00>;
			power-domains = <0x0c 0x08>;
			pcie-ctrl-sleep-shift = <0x0f>;
			pcie-hhi-mem-pd-shift = <0x1a>;
			pcie-hhi-mem-pd-mask = <0x0f>;
			pcie-ctrl-iso-shift = <0x0f>;
			status = "disable";
			reset-gpio = <0x2d 0x97 0x00>;
		};

		mmc@fe08c000 {
			compatible = "amlogic,meson-axg-mmc";
			reg = <0x00 0xfe08c000 0x00 0x800 0x00 0xfe000168 0x00 0x04 0x00 0xfe004000 0x00 0x04>;
			interrupts = <0x00 0xb2 0x01>;
			status = "okay";
			clocks = <0x0d 0x185 0x0d 0x119 0x0d 0x11b 0x2a 0x0d 0x11 0x0d 0x11>;
			clock-names = "core\0mux0\0mux1\0clkin0\0clkin1\0clkin2";
			card_type = <0x01>;
			src_clk_rate = <0x44aa2000>;
			mmc_debug_flag;
			ignore_desc_busy;
			tx_delay = <0x10>;
			nwr_cnt = <0x0c>;
			pinctrl-0 = <0x45 0x46>;
			pinctrl-1 = <0x47>;
			pinctrl-names = "default\0clk-gate";
			bus-width = <0x08>;
			cap-mmc-highspeed;
			mmc-ddr-1_8v;
			mmc-hs200-1_8v;
			mmc-hs400-1_8v;
			max-frequency = <0xbebc200>;
			non-removable;
			disable-wp;
		};

		sd@fe08a000 {
			compatible = "amlogic,meson-axg-mmc";
			reg = <0x00 0xfe08a000 0x00 0x800 0x00 0xfe00016c 0x00 0x04 0x00 0xfe00401c 0x00 0x04>;
			interrupts = <0x00 0xb1 0x01>;
			status = "okay";
			clocks = <0x0d 0x184 0x0d 0x11f 0x0d 0x121 0x2a 0x0d 0x05>;
			clock-names = "core\0mux0\0mux1\0clkin0\0clkin1";
			card_type = <0x05>;
			mmc_debug_flag;
			pinctrl-0 = <0x48>;
			pinctrl-1 = <0x49>;
			pinctrl-2 = <0x4a>;
			pinctrl-names = "sd_default\0sd_1bit_pins\0clk-gate";
			bus-width = <0x04>;
			cap-sd-highspeed;
			max-frequency = <0xbebc200>;
			disable-wp;
			cd-gpios = <0x2d 0x13 0x00>;
		};

		sdio@fe088000 {
			compatible = "amlogic,meson-axg-mmc";
			reg = <0x00 0xfe088000 0x00 0x800 0x00 0xfe00016c 0x00 0x04 0x00 0xfe004008 0x00 0x04>;
			interrupts = <0x00 0xb0 0x04>;
			status = "okay";
			clocks = <0x0d 0x183 0x0d 0x11c 0x0d 0x11e 0x2a 0x0d 0x05>;
			clock-names = "core\0mux0\0mux1\0clkin0\0clkin1";
			card_type = <0x03>;
			cap-sdio-irq;
			keep-power-in-suspend;
			use_intf3_tuning;
			mmc_debug_flag;
			pinctrl-0 = <0x4b>;
			pinctrl-1 = <0x4c>;
			pinctrl-names = "default\0clk-gate";
			#address-cells = <0x01>;
			#size-cells = <0x00>;
			bus-width = <0x04>;
			cap-sd-highspeed;
			sd-uhs-sdr50;
			sd-uhs-sdr104;
			max-frequency = <0xbebc200>;
			non-removable;
			disable-wp;

			wifi@1 {
				reg = <0x01>;
				compatible = "brcm,bcm4329-fmac";
			};
		};

		ethernet@fdc00000 {
			compatible = "amlogic,meson-axg-dwmac\0snps,dwmac-4.00";
			reg = <0x00 0xfdc00000 0x00 0x10000 0x00 0xfe024000 0x00 0x08>;
			interrupts = <0x00 0x4a 0x04>;
			interrupt-names = "macirq";
			power-domains = <0x0c 0x0f>;
			clocks = <0x0d 0x18c 0x0d 0x05 0x0d 0x31>;
			clock-names = "stmmaceth\0clkin0\0clkin1";
			rx-fifo-depth = <0x1000>;
			tx-fifo-depth = <0x800>;
			internal_phy = <0x01>;
			cali_val = <0x80000>;
			status = "okay";
			phy-handle = <0x4d>;
			phy-mode = "rmii";

			mdio {
				#address-cells = <0x01>;
				#size-cells = <0x00>;
				compatible = "snps,dwmac-mdio";
				phandle = <0x36>;
			};
		};

		serial@fe078000 {
			compatible = "amlogic,meson-uart";
			reg = <0x00 0xfe078000 0x00 0x18>;
			interrupts = <0x00 0xa8 0x01>;
			status = "okay";
			clocks = <0x2a>;
			clock-names = "clk_uart";
			xtal_tick_en = <0x02>;
			fifosize = <0x40>;
			pinctrl-names = "default";
		};

		serial@fe07c000 {
			compatible = "amlogic,meson-uart";
			reg = <0x00 0xfe07c000 0x00 0x18>;
			interrupts = <0x00 0xaa 0x01>;
			status = "okay";
			clocks = <0x2a 0x0d 0x18f>;
			clock-names = "clk_uart\0clk_gate";
			fifosize = <0x40>;
			pinctrl-names = "default";
			pinctrl-0 = <0x4e>;
			uart-has-rtscts;
		};

		serial@fe07e000 {
			compatible = "amlogic,meson-uart";
			status = "disabled";
			reg = <0x00 0xfe07e000 0x00 0x18>;
			interrupts = <0x00 0xab 0x01>;
			clocks = <0x2a 0x0d 0x190>;
			clock-names = "clk_uart\0clk_gate";
			fifosize = <0x40>;
			pinctrl-names = "default";
			pinctrl-0 = <0x4f>;
		};

		serial@fe080000 {
			compatible = "amlogic,meson-uart";
			status = "disabled";
			reg = <0x00 0xfe080000 0x00 0x18>;
			interrupts = <0x00 0xac 0x01>;
			clocks = <0x2a 0x0d 0x191>;
			clock-names = "clk_uart\0clk_gate";
			fifosize = <0x40>;
			pinctrl-names = "default";
			pinctrl-0 = <0x50>;
		};

		serial@fe082000 {
			compatible = "amlogic,meson-uart";
			status = "disabled";
			reg = <0x00 0xfe082000 0x00 0x18>;
			interrupts = <0x00 0xad 0x01>;
			clocks = <0x2a 0x0d 0x1c7>;
			clock-names = "clk_uart\0clk_gate";
			fifosize = <0x40>;
			pinctrl-names = "default";
			pinctrl-0 = <0x51>;
		};
	};

	mesonstream {
		compatible = "amlogic, codec, streambuf";
		dev_name = "mesonstream";
		status = "okay";
		clocks = <0x0d 0x17d 0x0d 0x92 0x0d 0x99 0x0d 0xa7 0x0d 0xa0>;
		clock-names = "vdec\0clk_vdec_mux\0clk_hcodec_mux\0clk_hevcf_mux\0clk_hevcb_mux";
		assigned-clock-parents = <0x0d 0x8e 0x0d 0xa3 0x0d 0x9c>;
		assigned-clocks = <0x0d 0x92 0x0d 0xa7 0x0d 0xa0>;
	};

	isp-sc@fe3b1400 {
		compatible = "amlogic, isp-sc";
		reg = <0x00 0xfe3b1400 0x00 0x400 0x00 0xfe3b1800 0x00 0x400 0x00 0xfe3b1c00 0x00 0x400 0x00 0xfe3b2000 0x00 0x400>;
		reg-names = "isp_sc0\0isp_sc1\0isp_sc2\0isp_crop";
		interrupts = <0x00 0x133 0x01 0x00 0x134 0x01 0x00 0x135 0x01 0x00 0x132 0x01>;
		interrupt-names = "isp_sc0\0isp_sc1\0isp_sc2\0isp_crop";
		phandle = <0x52>;
	};

	isp-md@fe3b2800 {
		compatible = "amlogic, isp-md";
		reg = <0x00 0xfe3b2800 0x00 0x400>;
		reg-names = "isp_md";
		interrupts = <0x00 0x13a 0x01>;
		interrupt-names = "isp_md";
		phandle = <0x55>;
	};

	isp-flicker@fe3b2c00 {
		compatible = "amlogic, isp-flicker";
		reg = <0x00 0xfe3b2c00 0x00 0x400>;
		reg-names = "isp_flicker";
		interrupts = <0x00 0x13b 0x01>;
		interrupt-names = "isp_flicker";
		phandle = <0x53>;
	};

	isp-cmpr@fe3b4000 {
		compatible = "amlogic, isp-cmpr";
		reg = <0x00 0xfe3b4000 0x00 0x1800 0x00 0xfe3b3000 0x00 0x1000>;
		reg-names = "isp_cmpr\0isp_top";
		interrupts = <0x00 0x13d 0x01 0x00 0x13c 0x01>;
		interrupt-names = "tnr_cmpr\0adapt_cmpr";
		phandle = <0x54>;
	};

	isp@fa000000 {
		compatible = "arm, isp";
		reg = <0x00 0xfa000000 0x00 0x40000>;
		reg-names = "ISP";
		interrupts = <0x00 0x121 0x04>;
		interrupt-names = "ISP";
		clk-level = <0x00>;
		clocks = <0x0d 0x136 0x0d 0x139>;
		clock-names = "cts_mipi_isp_clk\0cts_mipi_csi_phy_clk0";
		assigned-clock-parents = <0x0d 0x139>;
		assigned-clocks = <0x0d 0x13d>;
		power-domains = <0x0c 0x10 0x0c 0x11>;
		power-domain-names = "pwrc-isp\0pwrc-mipi";
		link-device = <0x52>;
		att-device = <0x53>;
		cmpr-device = <0x54>;
		md-device = <0x55>;
	};

	isp-adapter@fe3b0000 {
		compatible = "amlogic, isp-adapter";
		reg = <0x00 0xfe3b0000 0x00 0x5800 0x00 0xfe3b0800 0x00 0x400>;
		reg-names = "adapter\0adapter2";
		interrupts = <0x00 0x120 0x04>;
		interrupt-names = "adapter-irq";
		phandle = <0x56>;
	};

	phy-csi@fe3be000 {
		compatible = "amlogic, phy-csi";
		reg = <0x00 0xfe3bfc00 0x00 0x400 0x00 0xfe3bf800 0x00 0x400 0x00 0xfe3bf400 0x00 0x400 0x00 0xfe3bf000 0x00 0x400 0x00 0xfe3bdc00 0x00 0x100 0x00 0xfe3bec00 0x00 0x400 0x00 0xfe3be800 0x00 0x400 0x00 0xfe3be400 0x00 0x400 0x00 0xfe3be000 0x00 0x400>;
		reg-names = "csi2_phy0\0csi2_phy1\0csi2_phy2\0csi2_phy3\0aphy_reg\0csi0_host\0csi1_host\0csi2_host\0csi3_host";
		interrupts = <0x00 0x127 0x04 0x00 0x126 0x04 0x00 0x125 0x04 0x00 0x124 0x04 0x00 0x12f 0x04 0x00 0x12e 0x04 0x00 0x12d 0x04 0x00 0x12c 0x04 0x00 0x12b 0x04 0x00 0x12a 0x04 0x00 0x129 0x04 0x00 0x128 0x04>;
		interrupt-names = "phy0-irq\0phy1-irq\0phy2-irq\0phy3-irq\0csi-host0-intr1\0csi-host0-intr2\0csi-host1-intr1\0csi-host1-intr2\0csi-host2-intr1\0csi-host2-intr2\0csi-host3-intr1\0csi-host3-intr2";
		link-device = <0x56>;
	};

	vdec {
		compatible = "amlogic, vdec-pm-pd";
		dev_name = "vdec.0";
		status = "okay";
		interrupts = <0x00 0x03 0x01 0x00 0x17 0x01 0x00 0x20 0x01 0x00 0x5b 0x01 0x00 0x5c 0x01 0x00 0x5d 0x01 0x00 0x48 0x01>;
		interrupt-names = "vsync\0demux\0parser\0mailbox_0\0mailbox_1\0mailbox_2\0parser_b";
		power-domains = <0x0c 0x04 0x0c 0x02 0x0c 0x03 0x0c 0x05>;
		power-domain-names = "pwrc-vdec\0pwrc-hcodec\0pwrc-hevc\0pwrc-wave";
	};

	cpu_ver_name {
		compatible = "amlogic, cpu-major-id-t7";
	};

	vcodec_dec {
		compatible = "amlogic, vcodec-dec";
		dev_name = "aml-vcodec-dec";
		status = "okay";
	};

	multi-di {
		compatible = "amlogic, dim-t7";
		status = "okay";
		flag_cma = <0x04>;
		interrupts = <0x00 0xcb 0x01 0x00 0xca 0x01>;
		interrupt-names = "pre_irq\0post_irq";
		clocks = <0x0d 0xbc 0x0d 0xb7>;
		clock-names = "vpu_clkb\0vpu_mux";
		clock-range = <0x14e 0x29b>;
		buffer-size = <0x3e2c40>;
		post-wr-support = <0x01>;
		nr10bit-support = <0x01>;
		nrds-enable = <0x01>;
		pps-enable = <0x01>;
		en_4k = <0x00>;
		keep_dec_vf = <0x02>;
		po_fmt = <0x06>;
		post_nub = <0x0b>;
		alloc_sct = <0x00>;
		hf = <0x00>;
	};

	ddr_bandwidth {
		compatible = "amlogic,ddr-bandwidth-t7";
		status = "disabled";
		reg = <0x00 0xfe036000 0x00 0x400 0x00 0xfe034000 0x00 0x400 0x00 0xfe0a0000 0x00 0x100>;
		interrupts = <0x00 0x14c 0x01 0x00 0x150 0x01>;
		interrupt-names = "ddr_bandwidth";
	};

	dmc_monitor {
		compatible = "amlogic,dmc_monitor-t7";
		status = "okay";
		reg = <0x00 0xfe036000 0x00 0x400 0x00 0xfe034000 0x00 0x400>;
		reg_base = <0xfe036000>;
		interrupts = <0x00 0x14d 0x01 0x00 0x151 0x01>;
	};

	pmu@fe036000 {
		compatible = "amlogic,t7-ddr-pmu";
		reg = <0x00 0xfe036000 0x00 0x400 0x00 0xfe0a0000 0x00 0x100>;
		interrupts = <0x00 0x14c 0x01>;
	};

	pmu@fe034000 {
		compatible = "amlogic,t7-ddr-pmu";
		reg = <0x00 0xfe034000 0x00 0x400 0x00 0xfe0a0000 0x00 0x100>;
		interrupts = <0x00 0x150 0x01>;
	};

	amhdmitx {
		compatible = "amlogic, amhdmitx-t7";
		dev_name = "amhdmitx";
		status = "okay";
		power-domains = <0x0c 0x0e>;
		vend-data = <0x57>;
		pinctrl-names = "hdmitx_hpd\0hdmitx_ddc";
		pinctrl-0 = <0x58>;
		pinctrl-1 = <0x59>;
		interrupts = <0x00 0xcc 0x01>;
		interrupt-names = "hdmitx_hpd";
		aon_output = <0x00>;
		mboxes = <0x23 0x05>;
		enc_idx = <0x00>;
		reg = <0x00 0xff000000 0x00 0x40000 0x00 0xfe380000 0x00 0x10000 0x00 0xfe300000 0x00 0x10000 0x00 0xfe010000 0x00 0x2000 0x00 0xfe00c000 0x00 0x2000 0x00 0xfe008000 0x00 0x2000 0x00 0xfe002000 0x00 0x2000 0x00 0xfe000000 0x00 0x2000 0x00 0xfe004000 0x00 0x200>;
		reg-names = "vpu\0hdmitxcor\0hdmitxtop\0sysctrl\0pwrctrl\0anactrl\0resetctrl\0clkctrl\0padctrl";

		vend_data {
			vendor_name = "Amlogic";
			product_desc = "MBox Meson Ref";
			vendor_id = <0x00>;
			phandle = <0x57>;
		};

		ports {

			port {
				#address-cells = <0x01>;
				#size-cells = <0x00>;

				endpoint@0 {
					reg = <0x00>;
					remote-endpoint = <0x00>;
				};
			};
		};
	};

	aocec {
		compatible = "amlogic, aocec-t7";
		dev_name = "aocec";
		status = "disabled";
		vendor_name = "Amlogic";
		vendor_id = <0x00>;
		product_desc = "T7";
		cec_osd_string = "AML_TV";
		cec_version = <0x05>;
		port_num = <0x04>;
		output = <0x01>;
		cec_sel = <0x01>;
		ee_cec;
		arc_port_mask = <0x02>;
		interrupts = <0x00 0xb4 0x01 0x00 0xb3 0x01>;
		interrupt-names = "hdmi_aocecb\0hdmi_aocec";
		pinctrl-names = "default\0hdmitx_aocecb\0cec_pin_sleep";
		pinctrl-0 = <0x5a>;
		pinctrl-1 = <0x5a>;
		pinctrl-2 = <0x5a>;
		clocks = <0x0d 0x46 0x0d 0x4b>;
		clock-names = "ceca_clk\0cecb_clk";
		reg = <0x00 0xfe044000 0x00 0x2ff 0x00 0xfe010000 0x00 0xfff 0x00 0xfe000000 0x00 0xfff>;
		reg-names = "ao\0periphs\0clock";
	};

	aml_dma {
		compatible = "amlogic,aml_txlx_dma";
		reg = <0x00 0xfe440400 0x00 0x48>;
		interrupts = <0x00 0x18 0x01>;

		aml_aes {
			compatible = "amlogic,aes_g12a_dma";
			dev_name = "aml_aes_dma";
			status = "okay";
			iv_swap = [00];
		};

		aml_sha {
			compatible = "amlogic,sha_dma";
			dev_name = "aml_sha_dma";
			status = "okay";
		};

		aml_tdes {
			compatible = "amlogic,tdes_dma";
			dev_name = "aml_tdes_dma";
			status = "okay";
		};
	};

	rng {
		compatible = "amlogic,meson-rng";
		status = "okay";
		#address-cells = <0x02>;
		#size-cells = <0x02>;
		reg = <0x00 0xfe440788 0x00 0x0c>;
		quality = [03 e8];
		version = <0x02>;
	};

	canvas {
		compatible = "amlogic, meson, canvas";
		dev_name = "amlogic-canvas";
		status = "okay";
		reg = <0x00 0xfe036048 0x00 0x2000>;
	};

	codec_io {
		compatible = "amlogic, meson-t7, codec-io";
		status = "okay";
		#address-cells = <0x02>;
		#size-cells = <0x02>;
		ranges;
		reg = <0x00 0xfe002000 0x00 0x2000 0x00 0xfe320000 0x00 0x10000 0x00 0x00 0x00 0x00 0x00 0x00 0x00 0x00 0x00 0xff000000 0x00 0x40000 0x00 0xfe036000 0x00 0x2000 0x00 0x00 0x00 0x00 0x00 0xfe010000 0x00 0x168>;
		reg-names = "cbus\0dosbus\0hiubus\0aobus\0vcbus\0dmcbus\0efusebus\0gptbus";
	};

	jpegenc {
		compatible = "amlogic, jpegenc";
		dev_name = "jpegenc";
		status = "okay";
		clocks = <0x0d 0x17d 0x0d 0xca 0x0d 0x99>;
		clock-names = "clk_dos\0clk_apb_dos\0clk_jpeg_enc";
		power-domains = <0x0c 0x02>;
		interrupts = <0x00 0x5b 0x01 0x00 0x5c 0x01 0x00 0x5d 0x01>;
		interrupt-names = "dos_mbox_slow_irq0\0dos_mbox_slow_irq1\0dos_mbox_slow_irq2";
	};

	aml_enc {
		compatible = "cnm, MultiEnc";
		dev_name = "amvenc_multi";
		status = "okay";
		config_mm_sz_mb = <0xc8>;
		clocks = <0x0d 0x17d 0x0d 0xca 0x0d 0xaa 0x0d 0xad 0x0d 0xb0>;
		clock-names = "clk_dos\0clk_apb_dos\0clk_MultiEnc_A\0clk_MultiEnc_B\0clk_MultiEnc_C";
		interrupts = <0x00 0x5e 0x01 0x00 0x5f 0x01>;
		interrupt-names = "multienc_irq\0multienc_idle_irq";
		#address-cells = <0x02>;
		#size-cells = <0x02>;
		pwr-ctl = <0x00>;
		power-domains = <0x0c 0x05>;
		ranges;

		io_reg_base {
			reg = <0x00 0xfe310000 0x00 0x10000>;
		};
	};

	vpu {
		compatible = "amlogic, vpu-t7";
		status = "okay";
		reg = <0x00 0xfe000000 0x00 0x100 0x00 0xfe00c000 0x00 0x70 0x00 0xff000000 0x00 0xa000>;
		clocks = <0x0d 0xca 0x0d 0x1a9 0x0d 0xb3 0x0d 0xb6 0x0d 0xb7>;
		clock-names = "vapb_clk\0vpu_intr_gate\0vpu_clk0\0vpu_clk1\0vpu_clk";
		clk_level = <0x07>;
	};

	meson_uvm {
		compatible = "amlogic, meson_uvm";
		status = "okay";
	};

	meson_videotunnel {
		compatible = "amlogic, meson_videotunnel";
		status = "okay";
	};

	video_composer {
		compatible = "amlogic, video_composer";
		dev_name = "video_composer";
		status = "okay";
	};

	rdma {
		compatible = "amlogic, meson-t7, rdma";
		status = "okay";
		interrupts = <0x00 0xd7 0x01>;
		interrupt-names = "rdma";
		reset-names = "rdma";
		resets = <0x3b 0x1c>;
		rdma_table_page_count = <0x10>;
	};

	vclk_serve {
		compatible = "amlogic, vclk_serve";
		status = "okay";
		reg = <0x00 0xfe008000 0x00 0x400 0x00 0xfe000000 0x00 0x4a0>;
	};

	dummy_venc {
		compatible = "amlogic, dummy_venc_t7";
		status = "okay";
	};

	vout_mux {
		compatible = "amlogic, vout_mux-t7";
		status = "okay";
	};

	vout {
		compatible = "amlogic, vout";
		status = "okay";
	};

	vout2 {
		compatible = "amlogic, vout2";
		status = "okay";
	};

	vout3 {
		compatible = "amlogic, vout3";
		status = "okay";
	};

	vrr0 {
		compatible = "amlogic, vrr-t3";
		status = "okay";
		index = <0x00>;
	};

	vrr1 {
		compatible = "amlogic, vrr-t3";
		status = "okay";
		index = <0x01>;
	};

	vrr2 {
		compatible = "amlogic, vrr-t3";
		status = "okay";
		index = <0x02>;
	};

	ir@8000 {
		compatible = "amlogic, meson-ir";
		reg = <0x00 0xfe084040 0x00 0xa4 0x00 0xfe084000 0x00 0x20>;
		status = "okay";
		protocol = <0x01>;
		interrupts = <0x00 0x16 0x01>;
		demod_enable;
		pinctrl-0 = <0x5b>;
		pinctrl-names = "default";
		map = <0x5c>;
		max_frame_time = <0xc8>;
	};

	a73_tsensor@fe020000 {
		compatible = "amlogic, r1p1-tsensor";
		status = "okay";
		reg = <0x00 0xfe020000 0x00 0x50>;
		tsensor_id = <0x01>;
		cal_type = <0x11>;
		cal_coeff = <0x144 0x1a8 0xc57 0x24c3>;
		rtemp = <0x1c138>;
		interrupts = <0x00 0x1f 0x04>;
		clocks = <0x0d 0x84>;
		clock-names = "ts_comp";
		#thermal-sensor-cells = <0x01>;
	};

	a53_tsensor@fe022000 {
		compatible = "amlogic, r1p1-tsensor";
		status = "okay";
		reg = <0x00 0xfe022000 0x00 0x50>;
		tsensor_id = <0x02>;
		cal_type = <0x11>;
		cal_coeff = <0x144 0x1a8 0xc57 0x24c3>;
		rtemp = <0x1c138>;
		interrupts = <0x00 0x1e 0x04>;
		clocks = <0x0d 0x84>;
		clock-names = "ts_comp";
		#thermal-sensor-cells = <0x01>;
	};

	gpu_tsensor@fe094000 {
		compatible = "amlogic, r1p1-tsensor";
		status = "okay";
		reg = <0x00 0xfe094000 0x00 0x50>;
		tsensor_id = <0x03>;
		cal_type = <0x11>;
		cal_coeff = <0x144 0x1a8 0xc57 0x24c3>;
		rtemp = <0x1c138>;
		interrupts = <0x00 0x53 0x04>;
		clocks = <0x0d 0x84>;
		clock-names = "ts_comp";
		power-domains = <0x0c 0x1b>;
		#thermal-sensor-cells = <0x01>;
	};

	nna_tsensor@fe096000 {
		compatible = "amlogic, r1p1-tsensor";
		status = "okay";
		reg = <0x00 0xfe096000 0x00 0x50>;
		tsensor_id = <0x04>;
		cal_type = <0x11>;
		cal_coeff = <0x144 0x1a8 0xc57 0x24c3>;
		rtemp = <0x1c138>;
		interrupts = <0x00 0x54 0x04>;
		clocks = <0x0d 0x84>;
		clock-names = "ts_comp";
		power-domains = <0x0c 0x20>;
		#thermal-sensor-cells = <0x01>;
	};

	hevc_tsensor@fe09a000 {
		compatible = "amlogic, r1p1-tsensor";
		status = "okay";
		reg = <0x00 0xfe09a000 0x00 0x50>;
		tsensor_id = <0x05>;
		cal_type = <0x11>;
		cal_coeff = <0x144 0x1a8 0xc57 0x24c3>;
		rtemp = <0x1c138>;
		interrupts = <0x00 0x56 0x04>;
		clocks = <0x0d 0x84>;
		clock-names = "ts_comp";
		power-domains = <0x0c 0x03>;
		#thermal-sensor-cells = <0x01>;
	};

	vpu_tsensor@fe098000 {
		compatible = "amlogic, r1p1-tsensor";
		status = "okay";
		reg = <0x00 0xfe098000 0x00 0x50>;
		tsensor_id = <0x06>;
		cal_type = <0x11>;
		cal_coeff = <0x144 0x1a8 0xc57 0x24c3>;
		rtemp = <0x1c138>;
		interrupts = <0x00 0x55 0x04>;
		clocks = <0x0d 0x84>;
		clock-names = "ts_comp";
		power-domains = <0x0c 0x06>;
		#thermal-sensor-cells = <0x01>;
	};

	meson-cooldev@0 {
		status = "okay";
		compatible = "amlogic, meson-cooldev";

		cooling_devices {

			cpucore_cool_cluster0 {
				cluster_id = <0x00>;
				node_name = "cpucore_cool0";
				device_type = "cpucore";
			};

			cpucore_cool_cluster1 {
				cluster_id = <0x01>;
				node_name = "cpucore_cool1";
				device_type = "cpucore";
			};

			gpufreq_cool {
				dyn_coeff = <0x166>;
				node_name = "bifrost";
				device_type = "gpufreq";
			};
		};

		cpucore_cool0 {
			#cooling-cells = <0x02>;
		};

		cpucore_cool1 {
			#cooling-cells = <0x02>;
		};
	};

	ion_dev {
		compatible = "amlogic, ion_dev";
		memory-region = <0x5d 0x5e 0x5f>;
	};

	fb {
		compatible = "amlogic, fb-t7";
		memory-region = <0x60>;
		status = "okay";
		interrupts = <0x00 0xc5 0x01 0x00 0xc2 0x01 0x00 0x52 0x01 0x00 0xd7 0x01>;
		interrupt-names = "viu-vsync\0viu2-vsync\0viu3-vsync\0rdma";
		display_mode_default = "1080p60hz";
		scale_mode = <0x01>;
		display_size_default = <0x780 0x438 0x780 0x870 0x20>;
		mem_size = <0x800000 0x1980000 0x100000 0x100000 0x100000>;
		logo_addr = "0x3f800000";
		mem_alloc = <0x00>;
		pxp_mode = <0x00>;
	};

	meson-irblaster@fe08410c {
		compatible = "amlogic, meson_irblaster";
		status = "okay";
		reg = <0x00 0xfe08410c 0x00 0x10>;
		#irblaster-cells = <0x02>;
		pinctrl-names = "default";
		pinctrl-0 = <0x61>;
		interrupts = <0x00 0x17 0x01>;
	};

	vdin0 {
		compatible = "amlogic, vdin-t7";
		dev_name = "vdin0";
		reserve-iomap = "true";
		flag_cma = <0x101>;
		interrupts = <0x00 0xd2 0x01 0x00 0xd6 0x01>;
		interrupt-names = "vsync_int\0mif2_meta_wr_done_int";
		rdma-irq = <0x02>;
		clocks = <0x0d 0x0b 0x0d 0xce>;
		clock-names = "fclk_div5\0cts_vdin_meas_clk";
		vdin_id = <0x00>;
		tv_bit_mode = <0x235>;
		afbce_bit_mode = <0x11>;
		double_write_en;
		status = "okay";
		cma_size = <0x12c>;
		frame_buff_num = <0x0b>;
	};

	vdin1 {
		compatible = "amlogic, vdin-t7";
		dev_name = "vdin1";
		reserve-iomap = "true";
		flag_cma = <0x00>;
		interrupts = <0x00 0xd4 0x01>;
		interrupt-names = "vsync_int";
		rdma-irq = <0x04>;
		vdin_id = <0x01>;
		tv_bit_mode = <0x15>;
		memory-region = <0x62>;
		status = "okay";
	};

	amlvecm {
		compatible = "amlogic, vecm-t7";
		dev_name = "aml_vecm";
		clocks = <0x0d 0xdc>;
		clock-names = "cts_vid_lock_clk";
		status = "okay";
		gamma_en = <0x01>;
		wb_en = <0x00>;
		cm_en = <0x00>;
		wb_sel = <0x00>;
		vlock_en = <0x01>;
		vlock_mode = <0x08>;
		vlock_pll_m_limit = <0x01>;
		vlock_line_limit = <0x02>;
	};

	meson-amvideom {
		compatible = "amlogic, amvideom-t7";
		dev_name = "amvideom";
		status = "okay";
		interrupts = <0x00 0xc5 0x01 0x00 0xc2 0x01 0x00 0x52 0x01>;
		interrupt-names = "vsync\0vsync_viu2\0vsync_viu3";
	};

	vpu_security {
		compatible = "amlogic, meson-t7, vpu_security";
		dev_name = "amlogic-vpu-security";
		status = "okay";
		interrupts = <0x00 0xdc 0x01>;
		interrupt-names = "vpu_security";
	};

	aucpu {
		compatible = "amlogic, aucpu";
		dev_name = "aml_aucpu";
		status = "okay";
		interrupts = <0x00 0x4d 0x01>;
		interrupt-names = "aucpu_irq";
		#address-cells = <0x02>;
		#size-cells = <0x02>;
		ranges;

		io_reg_base {
			reg = <0x00 0xfe09e080 0x00 0x100>;
		};
	};

	ge2d {
		compatible = "amlogic, ge2d-t7";
		status = "okay";
		interrupts = <0x00 0xd9 0x01>;
		interrupt-names = "ge2d";
		clocks = <0x0d 0xca 0x0d 0x195 0x0d 0xcb>;
		clock-names = "clk_vapb_0\0clk_ge2d\0clk_ge2d_gate";
		reg = <0x00 0xff040000 0x00 0x100>;
		power-domains = <0x0c 0x09>;
	};

	aml_bt {
		compatible = "amlogic, aml-bt";
		status = "okay";
		reset-gpios = <0x2d 0x25 0x00>;
		hostwake-gpios = <0x2d 0x27 0x00>;
	};

	aml_wifi {
		compatible = "amlogic, aml-wifi";
		status = "okay";
		irq_trigger_type = "GPIO_IRQ_LOW";
		interrupt-gpios = <0x2d 0x1b 0x00>;
		power_on-gpios = <0x2d 0x1a 0x00>;
	};

	gdc {
		#address-cells = <0x02>;
		#size-cells = <0x02>;
		status = "okay";
		compatible = "amlogic, arm-gdc";
		reg = <0x00 0xfe08e000 0x00 0x100 0x00 0xfe0104c4 0x00 0x04>;
		interrupts = <0x00 0xdf 0x01>;
		interrupt-names = "gdc";
		clocks = <0x0d 0x140 0x0d 0x144 0x0d 0x145>;
		clock-names = "mux_gate\0mux_sel\0clk_gate";
		clk-rate = <0x2faf0800>;
		power-domains = <0x0c 0x12>;
	};

	amlgdc {
		#address-cells = <0x02>;
		#size-cells = <0x02>;
		status = "okay";
		compatible = "amlogic, aml-gdc";
		reg = <0x00 0xfe040000 0x00 0x15c>;
		interrupts = <0x00 0x3b 0x01>;
		interrupt-names = "amlgdc";
		clocks = <0x0d 0x148 0x0d 0x14c 0x0d 0x14d>;
		clock-names = "mux_gate\0mux_sel\0clk_gate";
		clk-rate = <0x2faf0800>;
		power-domains = <0x0c 0x13>;
	};

	mhu@0 {
		status = "okay";
		compatible = "amlogic, meson_mhu_fifo";
		reg = <0x00 0xfe006000 0x00 0x1000 0x00 0xfe007180 0x00 0x80 0x00 0xfe007200 0x00 0x80 0x00 0xfe007280 0x00 0x80 0x00 0xfe007040 0x00 0xc0>;
		interrupts = <0x00 0xf8 0x01>;
		mbox-irqmax = <0x40>;
		mbox-irqctlr = <0x00>;
		mbox-nums = <0x06>;
		mbox-names = "dsp_dev\0ap_to_dspa\0dspb_dev\0ap_to_dspb\0ao_dev\0ap_to_ao";
		mboxes = <0x23 0x00 0x23 0x01 0x23 0x02 0x23 0x03 0x23 0x04 0x23 0x05>;
		mbox-id = <0x00 0x01 0x06 0x07 0x02 0x03>;
		mbox-wr-rd = <0x01>;
		#mbox-cells = <0x01>;
		phandle = <0x23>;
	};

	lut_dma {
		compatible = "amlogic, meson-t7, lut_dma";
		status = "okay";
	};

	state_led {
		compatible = "amlogic,state-led-aocpu";
		status = "disabled";
	};

	efuse_burn {
		compatible = "amlogic, efuseburn";
		efuse_pattern_size = <0x600>;
		status = "okay";
	};

	efusecheck {
		maincmd = <0x8200003e>;
		checknum = <0x03>;
		check0 = <0x63>;
		check1 = <0x64>;
		check2 = <0x65>;
		phandle = <0x67>;

		check_0 {
			checkname = "dgpk1";
			subcmd = <0x1000>;
			phandle = <0x63>;
		};

		check_1 {
			checkname = "dgpk2";
			subcmd = <0x1001>;
			phandle = <0x64>;
		};

		check_2 {
			checkname = "aud_id";
			subcmd = <0x1002>;
			phandle = <0x65>;
		};
	};

	efuse {
		compatible = "amlogic, efuse";
		reg = <0x00 0xfe440040 0x00 0x04>;
		secureboot_mask = <0xc00>;
		mem_size = <0x100000>;
		read_cmd = <0x82000030>;
		write_cmd = <0x82000031>;
		get_max_cmd = <0x82000033>;
		mem_in_base_cmd = <0x82000020>;
		mem_out_base_cmd = <0x82000021>;
		efuse_pattern_size = <0x600>;
		key = <0x66>;
		check = <0x67>;
		clock-names = "efuse_clk";
		status = "okay";
	};

	efusekey {
		keynum = <0x04>;
		key0 = <0x68>;
		key1 = <0x69>;
		key2 = <0x6a>;
		key3 = <0x6b>;
		phandle = <0x66>;

		key_0 {
			keyname = "mac";
			offset = <0x00>;
			size = <0x06>;
			phandle = <0x68>;
		};

		key_1 {
			keyname = "mac_bt";
			offset = <0x06>;
			size = <0x06>;
			phandle = <0x69>;
		};

		key_2 {
			keyname = "mac_wifi";
			offset = <0x0c>;
			size = <0x06>;
			phandle = <0x6a>;
		};

		key_3 {
			keyname = "usid";
			offset = <0x12>;
			size = <0x10>;
			phandle = <0x6b>;
		};
	};

	gpu_opp_table {
		compatible = "operating-points-v2";
		phandle = <0x0b>;

		opp-285 {
			opp-hz = <0x00 0x1107a769>;
			opp-microvolt = <0x47e>;
		};

		opp-400 {
			opp-hz = <0x00 0x17d78400>;
			opp-microvolt = <0x47e>;
		};

		opp-500 {
			opp-hz = <0x00 0x1dcd6500>;
			opp-microvolt = <0x47e>;
		};

		opp-666 {
			opp-hz = <0x00 0x27bc86aa>;
			opp-microvolt = <0x47e>;
		};

		opp-800 {
			opp-hz = <0x00 0x2faf0800>;
			opp-microvolt = <0x47e>;
		};
	};

	firmware {

		android {
			compatible = "android,firmware";

			vbmeta {
				compatible = "android,vbmeta";
				parts = "vbmeta,boot,system,vendor";
				by_name_prefix = "/dev/block";
			};

			fstab {
				compatible = "android,fstab";

				vendor {
					compatible = "android,vendor";
					dev = "/dev/block/vendor";
					type = "ext4";
					mnt_flags = "ro,barrier=1,inode_readahead_blks=8";
					fsmgr_flags = "wait,avb";
				};

				product {
					compatible = "android,product";
					dev = "/dev/block/product";
					type = "ext4";
					mnt_flags = "ro,barrier=1,inode_readahead_blks=8";
					fsmgr_flags = "wait";
				};

				odm {
					compatible = "android,odm";
					dev = "/dev/block/odm";
					type = "ext4";
					mnt_flags = "ro,barrier=1,inode_readahead_blks=8";
					fsmgr_flags = "wait";
				};
			};
		};
	};

	partitions {
		parts = <0x10>;
		part-0 = <0x6c>;
		part-1 = <0x6d>;
		part-2 = <0x6e>;
		part-3 = <0x6f>;
		part-4 = <0x70>;
		part-5 = <0x71>;
		part-6 = <0x72>;
		part-7 = <0x73>;
		part-8 = <0x74>;
		part-9 = <0x75>;
		part-10 = <0x76>;
		part-11 = <0x77>;
		part-12 = <0x78>;
		part-13 = <0x79>;
		part-14 = <0x7a>;
		part-15 = <0x7b>;

		boot {
			pname = "boot";
			size = <0x00 0x2000000>;
			mask = <0x01>;
			phandle = <0x6e>;
		};

		vendor_boot {
			pname = "vendor_boot";
			size = <0x00 0x1800000>;
			mask = <0x01>;
			phandle = <0x6f>;
		};

		recovery {
			pname = "recovery";
			size = <0x00 0x2000000>;
			mask = <0x01>;
			phandle = <0x70>;
		};

		logo {
			pname = "logo";
			size = <0x00 0x400000>;
			mask = <0x01>;
			phandle = <0x71>;
		};

		tee {
			pname = "tee";
			size = <0x00 0x800000>;
			mask = <0x01>;
			phandle = <0x6d>;
		};

		misc {
			pname = "misc";
			size = <0x00 0x100000>;
			mask = <0x02>;
			phandle = <0x72>;
		};

		vendor {
			pname = "vendor";
			size = <0x00 0x12c00000>;
			mask = <0x01>;
			phandle = <0x75>;
		};

		nvcfg {
			pname = "nvcfg";
			size = <0x00 0x400000>;
			mask = <0x01>;
			phandle = <0x6c>;
		};

		cri_data {
			pname = "cri_data";
			size = <0x00 0x200000>;
			mask = <0x02>;
			phandle = <0x73>;
		};

		odm {
			pname = "odm";
			size = <0x00 0x800000>;
			mask = <0x01>;
			phandle = <0x76>;
		};

		vbmeta {
			pname = "vbmeta";
			size = <0x00 0x100000>;
			mask = <0x01>;
			phandle = <0x7a>;
		};

		system {
			pname = "system";
			size = <0x00 0xc2000000>;
			mask = <0x01>;
			phandle = <0x77>;
		};

		product {
			pname = "product";
			size = <0x00 0xc00000>;
			mask = <0x01>;
			phandle = <0x78>;
		};

		cache {
			pname = "cache";
			size = <0x00 0x6a400000>;
			mask = <0x02>;
			phandle = <0x79>;
		};

		param {
			pname = "param";
			size = <0x00 0x1000000>;
			mask = <0x02>;
			phandle = <0x74>;
		};

		data {
			pname = "data";
			size = <0xffffffff 0xffffffff>;
			mask = <0x04>;
			phandle = <0x7b>;
		};
	};

	lcd {
		compatible = "amlogic, lcd-t7";
		status = "okay";
		index = <0x00>;
		mode = "tablet";
		fr_auto_policy = <0x00>;
		key_valid = <0x00>;
		clocks = <0x0d 0x1b1 0x0d 0xd7 0x0d 0xd1>;
		clock-names = "dsi_host_gate\0dsi_phy_gate\0dsi_meas";
		reg = <0x00 0xfe018000 0x00 0x60 0x00 0xfe0b0000 0x00 0x10b0 0x00 0xfe074000 0x00 0x400 0x00 0xfe014000 0x00 0x200 0x00 0xfe002000 0x00 0xa0 0x00 0xfe004000 0x00 0x70>;
		interrupts = <0x00 0xc5 0x01 0x00 0xc2 0x01 0x00 0x52 0x01 0x00 0x11a 0x01>;
		interrupt-names = "vsync\0vsync2\0vsync3\0vbyone";
		pinctrl-names = "vbyone\0vbyone_off\0edp\0edp_off";
		pinctrl-0 = <0x7c>;
		pinctrl-1 = <0x7d>;
		pinctrl-2 = <0x7e>;
		pinctrl-3 = <0x7f>;
		pinctrl_version = <0x02>;
		lcd_cpu-gpios = <0x2d 0x9c 0x00>;
		lcd_cpu_gpio_names = "gpio_test_n0";

		lvds_0 {
			model_name = "768p-vfreq";
			interface = "lvds";
			basic_setting = <0x556 0x300 0x618 0x326 0x08 0x10 0x09>;
			range_setting = <0x5b4 0x7d0 0x310 0x3f7 0x2faf080 0x510ff40>;
			lcd_timing = <0x38 0x40 0x00 0x03 0x1c 0x00>;
			clk_attr = <0x02 0x0f 0x01 0x00>;
			lvds_attr = <0x01 0x00 0x00 0x00 0x00>;
			phy_attr = <0x03 0x00>;
			power_on_step = <0x00 0x00 0x01 0x32 0x02 0x00 0x00 0x00 0xff 0x00 0x00 0x00>;
			power_off_step = <0x02 0x00 0x00 0x0a 0x00 0x00 0x00 0x64 0xff 0x00 0x00 0x00>;
			backlight_index = <0xff>;
		};

		vbyone_0 {
			model_name = "public_2region";
			interface = "vbyone";
			basic_setting = <0xf00 0x870 0x1130 0x8ca 0x0a 0x10 0x09>;
			range_setting = <0x1090 0x12c0 0x898 0xac8 0x1c9c3800 0x25317c00>;
			lcd_timing = <0x21 0x1dd 0x00 0x06 0x41 0x00>;
			clk_attr = <0x02 0x00 0x01 0x00>;
			vbyone_attr = <0x08 0x02 0x04 0x04>;
			vbyone_intr_enable = <0x01 0x03>;
			phy_attr = <0x07 0x01>;
			hw_filter = <0x00 0x00>;
			power_on_step = <0x00 0x00 0x01 0xc8 0x02 0x00 0x00 0x0a 0xff 0x00 0x00 0x00>;
			power_off_step = <0x02 0x00 0x00 0x0a 0x00 0x00 0x00 0x1f4 0xff 0x00 0x00 0x00>;
			backlight_index = <0xff>;
		};

		vbyone_1 {
			model_name = "public_1region";
			interface = "vbyone";
			basic_setting = <0xf00 0x870 0x1130 0x8ca 0x0a 0x10 0x09>;
			range_setting = <0x1090 0x12c0 0x898 0xae6 0x20e6da00 0x25ab8e00>;
			lcd_timing = <0x21 0x1dd 0x00 0x06 0x41 0x00>;
			clk_attr = <0x02 0x00 0x01 0x00>;
			vbyone_attr = <0x08 0x01 0x04 0x04>;
			vbyone_intr_enable = <0x01 0x03>;
			phy_attr = <0x07 0x01>;
			hw_filter = <0x00 0x00>;
			power_on_step = <0x00 0x00 0x01 0xc8 0x02 0x00 0x00 0x0a 0xff 0x00 0x00 0x00>;
			power_off_step = <0x02 0x00 0x00 0x0a 0x00 0x00 0x00 0x1f4 0xff 0x00 0x00 0x00>;
			backlight_index = <0xff>;
		};

		vbyone_2 {
			model_name = "vbyone_1region_hdmi";
			interface = "vbyone";
			basic_setting = <0xf00 0x870 0x1130 0x8ca 0x0a 0x10 0x09>;
			range_setting = <0x1090 0x12c0 0x898 0xac8 0x1c9c3800 0x25317c00>;
			lcd_timing = <0x21 0x1dd 0x00 0x06 0x41 0x00>;
			clk_attr = <0x04 0x00 0x01 0x00>;
			vbyone_attr = <0x08 0x01 0x04 0x04>;
			vbyone_intr_enable = <0x01 0x03>;
			phy_attr = <0x07 0x01>;
			hw_filter = <0x00 0x00>;
			power_on_step = <0x00 0x00 0x01 0x14 0x02 0x00 0x00 0x00 0xff 0x00 0x00 0x00>;
			power_off_step = <0x02 0x00 0x00 0x14 0x00 0x00 0x00 0x64 0xff 0x00 0x00 0x00>;
			backlight_index = <0xff>;
		};

		vbyone_3 {
			model_name = "vbyone_2region_hdmi";
			interface = "vbyone";
			basic_setting = <0xf00 0x870 0x1130 0x8ca 0x0a 0x10 0x09>;
			range_setting = <0x1090 0x12c0 0x898 0xac8 0x1c9c3800 0x25317c00>;
			lcd_timing = <0x21 0x1dd 0x00 0x06 0x41 0x00>;
			clk_attr = <0x04 0x00 0x01 0x00>;
			vbyone_attr = <0x08 0x02 0x04 0x04>;
			vbyone_intr_enable = <0x01 0x03>;
			phy_attr = <0x07 0x01>;
			hw_filter = <0x00 0x00>;
			power_on_step = <0x00 0x00 0x01 0x14 0x02 0x00 0x00 0x00 0xff 0x00 0x00 0x00>;
			power_off_step = <0x02 0x00 0x00 0x14 0x00 0x00 0x00 0x64 0xff 0x00 0x00 0x00>;
			backlight_index = <0xff>;
		};

		edp_0 {
			model_name = "edp_1080p";
			interface = "edp";
			basic_setting = <0x780 0x438 0x898 0x465 0x08 0x10 0x09>;
			range_setting = <0x820 0xaa0 0x44c 0x564 0x7fbc320 0x94c5f00>;
			lcd_timing = <0x2c 0x94 0x00 0x05 0x1e 0x00>;
			clk_attr = <0x00 0x00 0x01 0x00>;
			edp_attr = <0x02 0x01 0x00 0x01 0x00 0x00 0x00 0x00 0x00>;
			phy_attr = <0x04 0x04>;
			power_on_step = <0x00 0x00 0x01 0x32 0x02 0x00 0x00 0x00 0xff 0x00 0x00 0x00>;
			power_off_step = <0x02 0x00 0x00 0x0a 0x00 0x00 0x00 0x1f4 0xff 0x00 0x00 0x00>;
			backlight_index = <0x00>;
		};

		mipi_0 {
			model_name = "TL070WSH27";
			interface = "mipi";
			basic_setting = <0x400 0x258 0x4e2 0x276 0x08 0x9a 0x56>;
			lcd_timing = <0x50 0x64 0x00 0x05 0x14 0x00>;
			clk_attr = <0x00 0x00 0x01 0x2d0fa50>;
			mipi_attr = <0x04 0x12c 0x00 0x01 0x00 0x02 0x01 0x00>;
			dsi_init_on = <0x05 0x01 0x11 0xfd 0x01 0x14 0x05 0x01 0x29 0xfd 0x01 0x14 0xff 0x00>;
			dsi_init_off = <0x05 0x01 0x28 0xfd 0x01 0x0a 0x05 0x01 0x10 0xfd 0x01 0x0a 0xff 0x00>;
			extern_init = <0xff>;
			power_on_step = <0x00 0x00 0x01 0x64 0x00 0x01 0x00 0x0a 0x00 0x01 0x01 0x14 0x02 0x00 0x00 0x00 0xff 0x00 0x00 0x00>;
			power_off_step = <0x02 0x00 0x00 0x32 0x00 0x01 0x00 0x0a 0x00 0x00 0x00 0x64 0xff 0x00 0x00 0x00>;
			backlight_index = <0x01>;
		};

		mipi_1 {
			model_name = "SLT_720P";
			interface = "mipi";
			basic_setting = <0x500 0x2d0 0x636 0x2ee 0x08 0x10 0x09>;
			lcd_timing = <0x28 0x3c 0x00 0x05 0x14 0x00>;
			clk_attr = <0x00 0x00 0x01 0x46cf710>;
			mipi_attr = <0x04 0x226 0x00 0x01 0x00 0x00 0x01 0x00>;
			dsi_init_on = <0x05 0x01 0x11 0xff 0xc8 0x05 0x01 0x29 0xff 0x14 0xff 0xff>;
			dsi_init_off = <0x05 0x01 0x28 0xff 0x0a 0x05 0x01 0x10 0xff 0x0a 0xff 0xff>;
			extern_init = <0xff>;
			power_on_step = <0x03 0x07 0x00 0x64 0x02 0x00 0x00 0x00 0xff 0x00 0x00 0x00>;
			power_off_step = <0x02 0x00 0x00 0x00 0xff 0x00 0x00 0x00>;
			backlight_index = <0xff>;
		};
	};

	backlight {
		compatible = "amlogic, backlight-t7";
		status = "okay";
		index = <0x00>;
		key_valid = <0x00>;
		pinctrl-names = "pwm_on\0pwm_off";
		pinctrl-0 = <0x80>;
		pinctrl-1 = <0x81>;
		pinctrl_version = <0x02>;
		interrupts = <0x00 0xc5 0x01 0x00 0xc2 0x01 0x00 0x52 0x01>;
		interrupt-names = "vsync\0vsync2\0vsync3";
		bl_pwm_config = <0x82>;
		bl-gpios = <0x2d 0x95 0x00 0x2d 0x3e 0x00>;
		bl_gpio_names = "GPIOH_1\0GPIOD_5";

		backlight_0 {
			index = <0x00>;
			bl_name = "backlight_pwm";
			bl_level_default_uboot_kernel = <0x5a 0x5a>;
			bl_level_attr = <0xff 0x01 0x80 0x80>;
			bl_ctrl_method = <0x01>;
			bl_power_attr = <0x00 0x01 0x00 0xc8 0xc8>;
			bl_pwm_port = "PWM_AO_H";
			bl_pwm_attr = <0x01 0x7d0 0xff 0x01>;
			bl_pwm_power = <0x01 0x00 0x0a 0x0a>;
			en_sequence_reverse = <0x00>;
		};

		backlight_1 {
			index = <0x01>;
			bl_name = "backlight_pwm";
			bl_level_default_uboot_kernel = <0xff 0xff>;
			bl_level_attr = <0xff 0x0a 0x80 0x80>;
			bl_ctrl_method = <0x01>;
			bl_power_attr = <0x00 0x01 0x00 0xc8 0xc8>;
			bl_pwm_port = "PWM_E";
			bl_pwm_attr = <0x00 0xb4 0x64 0x19>;
			bl_pwm_power = <0x01 0x00 0x0a 0x0a>;
			en_sequence_reverse = <0x00>;
		};
	};

	local_dimming_device {
		compatible = "amlogic, ldim_dev";
		status = "okay";
		key_valid = <0x00>;
		pinctrl-names = "ldim_pwm\0ldim_pwm_vs\0ldim_pwm_off";
		pinctrl-0 = <0x83>;
		pinctrl-1 = <0x84>;
		pinctrl-2 = <0x81>;
		pinctrl_version = <0x02>;
		ldim_pwm_config = <0x82>;
		ldim_dev-gpios = <0x2d 0x8d 0x00 0x2d 0x82 0x00 0x2d 0x8f 0x00>;
		ldim_dev_gpio_names = "GPIOY_12\0GPIOY_1\0GPIOY_14";

		ldim_dev_0 {
			index = <0x00>;
			type = <0x00>;
			ldim_dev_name = "ob3350";
			ldim_pwm_port = "PWM_D";
			ldim_pwm_attr = <0x00 0xc8 0x32>;
			en_gpio_on_off = <0x00 0x01 0x00>;
			dim_max_min = <0x64 0x14>;
		};

		ldim_dev_1 {
			index = <0x01>;
			type = <0x00>;
			ldim_dev_name = "global";
			ldim_pwm_port = "PWM_D";
			ldim_pwm_attr = <0x01 0xb4 0x32>;
			en_gpio_on_off = <0x00 0x01 0x00>;
			dim_max_min = <0x64 0x14>;
		};

		ldim_dev_2 {
			index = <0x02>;
			type = <0x01>;
			ldim_dev_name = "iw7027";
			ldim_pwm_port = "PWM_VS";
			ldim_pwm_attr = <0x01 0x02 0x32>;
			spi_bus_num = <0x02>;
			spi_chip_select = <0x00>;
			spi_max_frequency = <0xf4240>;
			spi_mode = <0x00>;
			spi_dma_support = <0x01>;
			spi_cs_delay = <0x0a 0x64>;
			en_gpio_on_off = <0x00 0x01 0x00>;
			lamp_err_gpio = <0xff>;
			spi_write_check = <0x00>;
			dim_max_min = <0xfff 0x00>;
			chip_count = <0x03>;
			ldim_zone_mapping = <0x25 0x26 0x27 0x28 0x29 0x20 0x21 0x22 0x23 0x24 0x10 0x11 0x12 0x13 0x14 0x2b 0x2c 0x2d 0x2e 0x2f 0x1b 0x1c 0x1d 0x1e 0x1f 0x15 0x16 0x17 0x18 0x19 0x09 0x08 0x07 0x06 0x05 0x04 0x03 0x02 0x01 0x00 0x0f 0x0e 0x0d 0x0c 0x0b>;
			ldim_bl_profile_mode = <0x02>;
			ldim_bl_profile_k_bits = <0xd9f 0x18>;
			ldim_bl_profile_path = "/odm/etc/tvconfig/panel/tcon/HV650QUB-F70_LDIM/bl_profile.bin";
			ldim_cus_param = <0x00 0x252 0x10c 0x7756 0x12ca8c 0x13fd616 0x00 0x4c4b40 0x00 0x00>;
			cmd_size = <0xff>;
			init_on = <0xc0 0x02 0x00 0x06 0xc0 0x02 0x01 0x00 0xc0 0x02 0x02 0x00 0xc0 0x02 0x03 0x00 0xc0 0x02 0x04 0x22 0xc0 0x02 0x05 0x00 0xc0 0x02 0x06 0x44 0xc0 0x02 0x07 0x00 0xc0 0x02 0x08 0x66 0xc0 0x02 0x09 0x00 0xc0 0x02 0x0a 0x88 0xc0 0x02 0x0b 0x00 0xc0 0x02 0x0c 0xaa 0xc0 0x02 0x0d 0x00 0xc0 0x02 0x0e 0xcc 0xc0 0x02 0x0f 0x00 0xc0 0x02 0x10 0xee 0xc0 0x02 0x11 0x51 0xc0 0x02 0x12 0x10 0xc0 0x02 0x13 0x32 0xc0 0x02 0x14 0x00 0xc0 0x02 0x15 0x54 0xc0 0x02 0x16 0x55 0xc0 0x02 0x17 0x76 0xc0 0x02 0x18 0x99 0xc0 0x02 0x19 0xbb 0xc0 0x02 0x1a 0xdd 0xc0 0x02 0x1b 0x00 0xc0 0x02 0x1c 0xa5 0xc0 0x02 0x1d 0x25 0xc0 0x02 0x1e 0x88 0xc0 0x02 0x1f 0x7e 0xc0 0x02 0x20 0x0a 0xc0 0x02 0x21 0xef 0xc0 0x02 0x22 0xff 0xc0 0x02 0x23 0xfb 0xc0 0x02 0x24 0xff 0xc0 0x02 0x25 0x00 0xc0 0x02 0x26 0x00 0xc0 0x02 0x27 0x33 0xc0 0x02 0x28 0x33 0xc0 0x02 0x29 0x87 0xc0 0x02 0x2a 0x1a 0xc0 0x02 0x2b 0x7f 0xc0 0x02 0x2c 0xac 0xc0 0x02 0x2d 0xff 0xc0 0x02 0x2e 0xe4 0xc0 0x02 0x2f 0xbc 0xc0 0x02 0x30 0xdd 0xc0 0x02 0x31 0x82 0xc0 0x02 0x32 0x85 0xc0 0x02 0x33 0x16 0xc0 0x02 0x34 0x98 0xc0 0x02 0x35 0xbf 0xc0 0x02 0x36 0x41 0xc0 0x02 0x37 0x00 0xc0 0x02 0x38 0xc0 0xc0 0x02 0x39 0x00 0xc0 0x02 0x40 0x08 0xc0 0x02 0x41 0x00 0xc0 0x02 0x42 0x08 0xc0 0x02 0x43 0x00 0xc0 0x02 0x44 0x08 0xc0 0x02 0x45 0x00 0xc0 0x02 0x46 0x08 0xc0 0x02 0x47 0x00 0xc0 0x02 0x48 0x08 0xc0 0x02 0x49 0x00 0xc0 0x02 0x4a 0x08 0xc0 0x02 0x4b 0x00 0xc0 0x02 0x4c 0x08 0xc0 0x02 0x4d 0x00 0xc0 0x02 0x4e 0x08 0xc0 0x02 0x4f 0x00 0xc0 0x02 0x50 0x08 0xc0 0x02 0x51 0x00 0xc0 0x02 0x52 0x08 0xc0 0x02 0x53 0x00 0xc0 0x02 0x54 0x08 0xc0 0x02 0x55 0x00 0xc0 0x02 0x56 0x08 0xc0 0x02 0x57 0x00 0xc0 0x02 0x58 0x08 0xc0 0x02 0x59 0x00 0xc0 0x02 0x5a 0x08 0xc0 0x02 0x5b 0x00 0xc0 0x02 0x5c 0x08 0xc0 0x02 0x5d 0x00 0xc0 0x02 0x5e 0x08 0xc0 0x02 0x5f 0x00 0xff 0x00>;
			init_off = <0xff 0x00>;
		};
	};

	lcd1 {
		compatible = "amlogic, lcd-t7";
		status = "okay";
		index = <0x01>;
		mode = "tablet";
		fr_auto_policy = <0x00>;
		key_valid = <0x00>;
		clocks = <0x0d 0x1b2 0x0d 0xda 0x0d 0xd4>;
		clock-names = "dsi_host_gate\0dsi_phy_gate\0dsi_meas";
		reg = <0x00 0xfe018000 0x00 0x60 0x00 0xfe0b2000 0x00 0x10b0 0x00 0xfe072000 0x00 0x400 0x00 0xfe016000 0x00 0x200 0x00 0xfe002000 0x00 0xa0 0x00 0xfe004000 0x00 0x70>;
		interrupts = <0x00 0xc5 0x01 0x00 0xc2 0x01 0x00 0x52 0x01 0x00 0x11b 0x01>;
		interrupt-names = "vsync\0vsync2\0vsync3\0vbyone";
		pinctrl-names = "vbyone\0vbyone_off\0edp\0edp_off";
		pinctrl-0 = <0x85>;
		pinctrl-1 = <0x86>;
		pinctrl-2 = <0x87>;
		pinctrl-3 = <0x88>;
		pinctrl_version = <0x02>;
		lcd_cpu-gpios = <0x2d 0x8f 0x00 0x2d 0x87 0x00>;
		lcd_cpu_gpio_names = "GPIOY_14\0GPIOY_6";

		lvds_0 {
			model_name = "768p-vfreq";
			interface = "lvds";
			basic_setting = <0x556 0x300 0x618 0x326 0x08 0x10 0x09>;
			range_setting = <0x5b4 0x7d0 0x310 0x3f7 0x2faf080 0x510ff40>;
			lcd_timing = <0x38 0x40 0x00 0x03 0x1c 0x00>;
			clk_attr = <0x02 0x0f 0x01 0x00>;
			lvds_attr = <0x01 0x00 0x00 0x00 0x00>;
			phy_attr = <0x03 0x00>;
			power_on_step = <0x00 0x00 0x01 0x32 0x02 0x00 0x00 0x00 0xff 0x00 0x00 0x00>;
			power_off_step = <0x02 0x00 0x00 0x0a 0x00 0x00 0x00 0x64 0xff 0x00 0x00 0x00>;
			backlight_index = <0xff>;
		};

		vbyone_0 {
			model_name = "public_2region";
			interface = "vbyone";
			basic_setting = <0xf00 0x870 0x1130 0x8ca 0x0a 0x10 0x09>;
			range_setting = <0x1090 0x12c0 0x898 0xac8 0x1c9c3800 0x25317c00>;
			lcd_timing = <0x21 0x1dd 0x00 0x06 0x41 0x00>;
			clk_attr = <0x02 0x00 0x01 0x00>;
			vbyone_attr = <0x08 0x02 0x04 0x04>;
			vbyone_intr_enable = <0x01 0x03>;
			phy_attr = <0x07 0x01>;
			hw_filter = <0x00 0x00>;
			power_on_step = <0x00 0x00 0x01 0xc8 0x02 0x00 0x00 0x0a 0xff 0x00 0x00 0x00>;
			power_off_step = <0x02 0x00 0x00 0x0a 0x00 0x00 0x00 0x1f4 0xff 0x00 0x00 0x00>;
			backlight_index = <0xff>;
		};

		vbyone_1 {
			model_name = "public_1region";
			interface = "vbyone";
			basic_setting = <0xf00 0x870 0x1130 0x8ca 0x0a 0x10 0x09>;
			range_setting = <0x1090 0x12c0 0x898 0xae6 0x20e6da00 0x25ab8e00>;
			lcd_timing = <0x21 0x1dd 0x00 0x06 0x41 0x00>;
			clk_attr = <0x02 0x00 0x01 0x00>;
			vbyone_attr = <0x08 0x01 0x04 0x04>;
			vbyone_intr_enable = <0x01 0x03>;
			phy_attr = <0x07 0x01>;
			hw_filter = <0x00 0x00>;
			power_on_step = <0x00 0x00 0x01 0xc8 0x02 0x00 0x00 0x0a 0xff 0x00 0x00 0x00>;
			power_off_step = <0x02 0x00 0x00 0x0a 0x00 0x00 0x00 0x1f4 0xff 0x00 0x00 0x00>;
			backlight_index = <0xff>;
		};

		vbyone_2 {
			model_name = "vbyone_1region_hdmi";
			interface = "vbyone";
			basic_setting = <0xf00 0x870 0x1130 0x8ca 0x0a 0x10 0x09>;
			range_setting = <0x1090 0x12c0 0x898 0xac8 0x1c9c3800 0x25317c00>;
			lcd_timing = <0x21 0x1dd 0x00 0x06 0x41 0x00>;
			clk_attr = <0x04 0x00 0x01 0x00>;
			vbyone_attr = <0x08 0x01 0x04 0x04>;
			vbyone_intr_enable = <0x01 0x03>;
			phy_attr = <0x07 0x01>;
			hw_filter = <0x00 0x00>;
			power_on_step = <0x00 0x00 0x01 0x14 0x02 0x00 0x00 0x00 0xff 0x00 0x00 0x00>;
			power_off_step = <0x02 0x00 0x00 0x14 0x00 0x00 0x00 0x64 0xff 0x00 0x00 0x00>;
			backlight_index = <0xff>;
		};

		vbyone_3 {
			model_name = "vbyone_2region_hdmi";
			interface = "vbyone";
			basic_setting = <0xf00 0x870 0x1130 0x8ca 0x0a 0x10 0x09>;
			range_setting = <0x1090 0x12c0 0x898 0xac8 0x1c9c3800 0x25317c00>;
			lcd_timing = <0x21 0x1dd 0x00 0x06 0x41 0x00>;
			clk_attr = <0x04 0x00 0x01 0x00>;
			vbyone_attr = <0x08 0x02 0x04 0x04>;
			vbyone_intr_enable = <0x01 0x03>;
			phy_attr = <0x07 0x01>;
			hw_filter = <0x00 0x00>;
			power_on_step = <0x00 0x00 0x01 0x14 0x02 0x00 0x00 0x00 0xff 0x00 0x00 0x00>;
			power_off_step = <0x02 0x00 0x00 0x14 0x00 0x00 0x00 0x64 0xff 0x00 0x00 0x00>;
			backlight_index = <0xff>;
		};

		edp_0 {
			model_name = "edp_1080p";
			interface = "edp";
			basic_setting = <0x780 0x438 0x898 0x465 0x08 0x10 0x09>;
			range_setting = <0x820 0xaa0 0x44c 0x564 0x7fbc320 0x94c5f00>;
			lcd_timing = <0x2c 0x94 0x00 0x05 0x1e 0x00>;
			clk_attr = <0x00 0x00 0x01 0x00>;
			edp_attr = <0x02 0x01 0x00 0x00 0x00 0x00 0x00 0x00 0x00>;
			phy_attr = <0x05 0x01>;
			power_on_step = <0x00 0x00 0x01 0x32 0x02 0x00 0x00 0x00 0xff 0x00 0x00 0x00>;
			power_off_step = <0x02 0x00 0x00 0x0a 0x00 0x00 0x00 0xc8 0xff 0x00 0x00 0x00>;
			backlight_index = <0x00>;
		};

		mipi_0 {
			model_name = "TL070WSH27";
			interface = "mipi";
			basic_setting = <0x400 0x258 0x4e2 0x276 0x08 0x9a 0x56>;
			lcd_timing = <0x50 0x64 0x00 0x05 0x14 0x00>;
			clk_attr = <0x00 0x00 0x01 0x2d0fa50>;
			mipi_attr = <0x04 0x12c 0x00 0x01 0x00 0x02 0x01 0x00>;
			dsi_init_on = <0x05 0x01 0x11 0xfd 0x01 0x14 0x05 0x01 0x29 0xfd 0x01 0x14 0xff 0x00>;
			dsi_init_off = <0x05 0x01 0x28 0xfd 0x01 0x0a 0x05 0x01 0x10 0xfd 0x01 0x0a 0xff 0x00>;
			extern_init = <0xff>;
			power_on_step = <0x00 0x00 0x01 0x64 0x00 0x01 0x00 0x0a 0x00 0x01 0x01 0x14 0x02 0x00 0x00 0x00 0xff 0x00 0x00 0x00>;
			power_off_step = <0x02 0x00 0x00 0x32 0x00 0x01 0x00 0x0a 0x00 0x00 0x00 0x64 0xff 0x00 0x00 0x00>;
			backlight_index = <0x01>;
		};

		mipi_1 {
			model_name = "SLT_720P";
			interface = "mipi";
			basic_setting = <0x500 0x2d0 0x636 0x2ee 0x08 0x10 0x09>;
			lcd_timing = <0x28 0x3c 0x00 0x05 0x14 0x00>;
			clk_attr = <0x00 0x00 0x01 0x46cf710>;
			mipi_attr = <0x04 0x226 0x00 0x01 0x00 0x00 0x01 0x00>;
			dsi_init_on = <0x05 0x01 0x11 0xff 0xc8 0x05 0x01 0x29 0xff 0x14 0xff 0xff>;
			dsi_init_off = <0x05 0x01 0x28 0xff 0x0a 0x05 0x01 0x10 0xff 0x0a 0xff 0xff>;
			extern_init = <0xff>;
			power_on_step = <0x03 0x07 0x00 0x64 0x02 0x00 0x00 0x00 0xff 0x00 0x00 0x00>;
			power_off_step = <0x02 0x00 0x00 0x00 0xff 0x00 0x00 0x00>;
			backlight_index = <0xff>;
		};
	};

	backlight1 {
		compatible = "amlogic, backlight-t7";
		status = "okay";
		index = <0x01>;
		key_valid = <0x00>;
		pinctrl-names = "pwm_on\0pwm_off";
		pinctrl-0 = <0x89>;
		pinctrl-1 = <0x8a>;
		pinctrl_version = <0x02>;
		interrupts = <0x00 0xc5 0x01 0x00 0xc2 0x01 0x00 0x52 0x01>;
		interrupt-names = "vsync\0vsync2\0vsync3";
		bl_pwm_config = <0x82>;
		bl-gpios = <0x2d 0x8e 0x00 0x2d 0x89 0x00>;
		bl_gpio_names = "GPIOY_13\0GPIOY_8";

		backlight_0 {
			index = <0x00>;
			bl_name = "backlight_pwm";
			bl_level_default_uboot_kernel = <0xff 0xff>;
			bl_level_attr = <0xff 0x0a 0x80 0x80>;
			bl_ctrl_method = <0x01>;
			bl_power_attr = <0x00 0x01 0x00 0xc8 0xc8>;
			bl_pwm_port = "PWM_F";
			bl_pwm_attr = <0x01 0xb4 0x64 0x19>;
			bl_pwm_power = <0x01 0x00 0x0a 0x0a>;
			en_sequence_reverse = <0x00>;
		};

		backlight_1 {
			index = <0x01>;
			bl_name = "backlight_pwm";
			bl_level_default_uboot_kernel = <0xff 0xff>;
			bl_level_attr = <0xff 0x0a 0x80 0x80>;
			bl_ctrl_method = <0x01>;
			bl_power_attr = <0x00 0x01 0x00 0xc8 0xc8>;
			bl_pwm_port = "PWM_F";
			bl_pwm_attr = <0x00 0xb4 0x64 0x19>;
			bl_pwm_power = <0x01 0x00 0x0a 0x0a>;
			en_sequence_reverse = <0x00>;
		};
	};

	lcd2 {
		compatible = "amlogic, lcd-t7";
		status = "okay";
		index = <0x02>;
		mode = "tablet";
		fr_auto_policy = <0x00>;
		key_valid = <0x00>;
		reg = <0x00 0xfe018000 0x00 0x60 0x00 0xfe0b0000 0x00 0x10b0 0x00 0xfe074000 0x00 0x400 0x00 0xfe014000 0x00 0x200 0x00 0xfe002000 0x00 0xa0 0x00 0xfe004000 0x00 0x70>;
		interrupts = <0x00 0xc5 0x01 0x00 0xc2 0x01 0x00 0x52 0x01>;
		interrupt-names = "vsync\0vsync2\0vsync3";
		pinctrl_version = <0x02>;
		lcd_cpu-gpios = <0x2d 0x9c 0x00>;
		lcd_cpu_gpio_names = "gpio_test_n0";

		lvds_0 {
			model_name = "1080p-vfreq";
			interface = "lvds";
			basic_setting = <0x780 0x438 0x898 0x465 0x08 0x10 0x09>;
			range_setting = <0x80c 0xa5a 0x44c 0x5c8 0x7270e00 0x9896800>;
			lcd_timing = <0x2c 0x94 0x00 0x05 0x1e 0x00>;
			clk_attr = <0x02 0x00 0x01 0x00>;
			lvds_attr = <0x01 0x01 0x00 0x00 0x00>;
			phy_attr = <0x03 0x00>;
			power_on_step = <0x00 0x00 0x01 0x32 0x02 0x00 0x00 0x00 0xff 0x00 0x00 0x00>;
			power_off_step = <0x02 0x00 0x00 0x0a 0x00 0x00 0x00 0x64 0xff 0x00 0x00 0x00>;
			backlight_index = <0xff>;
		};

		lvds_1 {
			model_name = "1080p-mv215-mn215";
			interface = "lvds";
			basic_setting = <0x780 0x438 0x898 0x465 0x08 0x10 0x09>;
			range_setting = <0x820 0xaa0 0x44c 0x564 0x7fbc320 0x94c5f00>;
			lcd_timing = <0x2c 0x94 0x00 0x05 0x1e 0x00>;
			clk_attr = <0x02 0x00 0x01 0x00>;
			lvds_attr = <0x01 0x01 0x00 0x00 0x00>;
			phy_attr = <0x03 0x00>;
			power_on_step = <0x00 0x00 0x01 0x14 0x02 0x00 0x00 0x00 0xff 0x00 0x00 0x00>;
			power_off_step = <0x02 0x00 0x00 0x0a 0x00 0x00 0x00 0x1f4 0xff 0x00 0x00 0x00>;
			backlight_index = <0xff>;
		};
	};

	bl_pwm_conf {
		phandle = <0x82>;

		pwm_channel_0 {
			pwm_port = "PWM_AO_H";
			pwms = <0x8b 0x01 0x7558 0x00>;
		};
	};

	aliases {
		serial0 = "/soc/serial@fe078000";
		serial1 = "/soc/serial@fe07c000";
		serial2 = "/soc/apb4@fe000000/serial@7a000";
		serial3 = "/soc/serial@fe07e000";
		serial4 = "/soc/serial@fe080000";
		serial5 = "/soc/serial@fe082000";
		i2c0 = "/soc/apb4@fe000000/i2c@66000";
		i2c1 = "/soc/apb4@fe000000/i2c@68000";
		i2c2 = "/soc/apb4@fe000000/i2c@6a000";
		i2c3 = "/soc/apb4@fe000000/i2c@6c000";
		i2c4 = "/soc/apb4@fe000000/i2c@6e000";
		i2c5 = "/soc/apb4@fe000000/i2c@70000";
		i2c6 = "/soc/apb4@fe000000/i2c@76000";
		i2c7 = "/soc/apb4@fe000000/i2c@86000";
		spi0 = "/soc/apb4@fe000000/spi@56000";
		spi1 = "/soc/apb4@fe000000/spi@50000";
		spi2 = "/soc/apb4@fe000000/spi@52000";
		spi3 = "/soc/apb4@fe000000/spi@54000";
		spi4 = "/soc/apb4@fe000000/spi@4a000";
		spi5 = "/soc/apb4@fe000000/spi@4c000";
		spi6 = "/soc/apb4@fe000000/spi@4e000";
		ethernet0 = "/soc/ethernet@fdc00000";
		tsensor0 = "/a73_tsensor@fe020000";
		tsensor1 = "/a53_tsensor@fe022000";
		tsensor2 = "/gpu_tsensor@fe094000";
		tsensor3 = "/nna_tsensor@fe096000";
		tsensor4 = "/hevc_tsensor@fe09a000";
		tsensor5 = "/vpu_tsensor@fe098000";
	};

	memory@00000000 {
		device_type = "memory";
		linux,usable-memory = <0x00 0x00 0x00 0x80000000>;
	};

	codec_mm {
		compatible = "amlogic, codec, mm";
		memory-region = <0x8c 0x8d>;
		dev_name = "codec_mm";
		status = "okay";
	};

	cvbsout {
		compatible = "amlogic, cvbsout-sc2";
		status = "disabled";
		clk_path = <0x00>;
		performance = <0x1bf0 0x09 0x1b56 0x333 0x1b12 0x8080 0x1b05 0xfd 0x1c59 0xf850 0xffff 0x00>;
		performance_sarft = <0x1bf0 0x09 0x1b56 0x333 0x1b12 0x00 0x1b05 0x09 0x1c59 0xfc48 0xffff 0x00>;
		performance_revB_telecom = <0x1bf0 0x09 0x1b56 0x546 0x1b12 0x8080 0x1b05 0x09 0x1c59 0xf850 0xffff 0x00>;
	};

	provisionkey {
		compatible = "amlogic, provisionkey";
		status = "okay";
		key-permit-default = "write";

		KEY_PROVISION_XXX {
		};
	};

	unifykey {
		compatible = "amlogic,unifykey";
		status = "okay";
		unifykey-num = <0x13>;
		unifykey-index-0 = <0x8e>;
		unifykey-index-1 = <0x8f>;
		unifykey-index-2 = <0x90>;
		unifykey-index-3 = <0x91>;
		unifykey-index-4 = <0x92>;
		unifykey-index-5 = <0x93>;
		unifykey-index-6 = <0x94>;
		unifykey-index-7 = <0x95>;
		unifykey-index-8 = <0x96>;
		unifykey-index-9 = <0x97>;
		unifykey-index-10 = <0x98>;
		unifykey-index-11 = <0x99>;
		unifykey-index-12 = <0x9a>;
		unifykey-index-13 = <0x9b>;
		unifykey-index-14 = <0x9c>;
		unifykey-index-15 = <0x9d>;
		unifykey-index-16 = <0x9e>;
		unifykey-index-17 = <0x9f>;
		unifykey-index-18 = <0xa0>;
		unifykey-index-19 = <0xa1>;
		unifykey-index-20 = <0xa2>;
		unifykey-index-21 = <0xa3>;

		key_0 {
			key-name = "usid";
			key-device = "normal";
			key-permit = "read\0write\0del";
			phandle = <0x8e>;
		};

		key_1 {
			key-name = "mac";
			key-device = "normal";
			key-permit = "read\0write\0del";
			phandle = <0x8f>;
		};

		key_2 {
			key-name = "hdcp";
			key-device = "secure";
			key-type = "sha1";
			key-permit = "read\0write\0del";
			phandle = <0x90>;
		};

		key_3 {
			key-name = "secure_boot_set";
			key-device = "efuse";
			key-permit = "write";
			phandle = <0x91>;
		};

		key_4 {
			key-name = "mac_bt";
			key-device = "normal";
			key-permit = "read\0write\0del";
			key-type = "mac";
			phandle = <0x92>;
		};

		key_5 {
			key-name = "mac_wifi";
			key-device = "normal";
			key-permit = "read\0write\0del";
			key-type = "mac";
			phandle = <0x93>;
		};

		key_6 {
			key-name = "hdcp2_tx";
			key-device = "normal";
			key-permit = "read\0write\0del";
			phandle = <0x94>;
		};

		key_7 {
			key-name = "hdcp2_rx";
			key-device = "normal";
			key-permit = "read\0write\0del";
			phandle = <0x95>;
		};

		key_8 {
			key-name = "widevinekeybox";
			key-device = "secure";
			key-permit = "read\0write\0del";
			phandle = <0x96>;
		};

		key_9 {
			key-name = "deviceid";
			key-device = "normal";
			key-permit = "read\0write\0del";
			phandle = <0x97>;
		};

		key_10 {
			key-name = "hdcp22_fw_private";
			key-device = "secure";
			key-permit = "read\0write\0del";
			phandle = <0x98>;
		};

		key_11 {
			key-name = "PlayReadykeybox25";
			key-device = "secure";
			key-permit = "read\0write\0del";
			phandle = <0x99>;
		};

		key_12 {
			key-name = "prpubkeybox";
			key-device = "secure";
			key-permit = "read\0write\0del";
			phandle = <0x9a>;
		};

		key_13 {
			key-name = "prprivkeybox";
			key-device = "secure";
			key-permit = "read\0write\0del";
			phandle = <0x9b>;
		};

		key_14 {
			key-name = "attestationkeybox";
			key-device = "secure";
			key-permit = "read\0write\0del";
			phandle = <0x9c>;
		};

		key_15 {
			key-name = "region_code";
			key-device = "normal";
			key-permit = "read\0write\0del";
			phandle = <0x9d>;
		};

		key_16 {
			key-name = "netflix_mgkid";
			key-device = "secure";
			key-permit = "read\0write\0del";
			phandle = <0x9e>;
		};

		key_17 {
			key-name = "attestationdevidbox";
			key-device = "secure";
			key-permit = "read\0write\0del";
			phandle = <0x9f>;
		};

		key_18 {
			key-name = "oemkey";
			key-device = "normal";
			key-permit = "read\0write\0del";
			phandle = <0xa0>;
		};

		key_19 {
			key-name = "lcd";
			key-device = "normal";
			key-permit = "read\0write\0del";
			phandle = <0xa1>;
		};

		key_20 {
			key-name = "lcd_extern";
			key-device = "normal";
			key-permit = "read\0write\0del";
			phandle = <0xa2>;
		};

		key_21 {
			key-name = "backlight";
			key-device = "normal";
			key-permit = "read\0write\0del";
			phandle = <0xa3>;
		};
	};

	clock-pmic {
		compatible = "fixed-clock";
		#clock-cells = <0x00>;
		clock-frequency = <0x8000>;
		clock-output-names = "pmic_osc";
		phandle = <0x33>;
	};

	hdmirx {
		compatible = "amlogic, hdmirx_t7";
		#address-cells = <0x01>;
		#size-cells = <0x01>;
		status = "okay";
		pinctrl-names = "hdmirx_pins";
		pinctrl-0 = <0xa4 0xa5 0xa6>;
		repeat = <0x00>;
		power-domains = <0x0c 0x0c>;
		interrupts = <0x00 0x39 0x04>;
		clocks = <0x0d 0x167 0x0d 0x170 0x0d 0x173 0x0d 0x161 0x0d 0x164 0x0d 0x16a 0x2a 0x0d 0x09 0x0d 0x0b>;
		clock-names = "hdmirx_cfg_clk\0cts_hdmirx_acr_ref_clk\0cts_hdmirx_meter_clk\0cts_hdmirx_2m_clk\0cts_hdmirx_5m_clk\0cts_hdmirx_hdcp2x_eclk\0xtal\0fclk_div4\0fclk_div5";
		hdmirx_id = <0x00>;
		en_4k_2_2k = <0x00>;
		hpd_low_cec_off = <0x00>;
		arc_port = <0x01>;
		disable_port = <0x00>;
		reg = <0x00 0x00 0x00 0x00 0x00 0xff63c000 0x00 0x2000 0x00 0xffe0d000 0x00 0x2000 0x00 0x00 0x00 0x00 0x00 0x00 0x00 0x00 0x00 0x00 0x00 0x00 0x00 0xfe398000 0x00 0x18000 0x00 0xfe000000 0x00 0x1fff>;
	};

	auge_sound {
		compatible = "amlogic, auge-sound-card";
		aml-audio-card,name = "AML-AUGESOUND";
		avout_mute-gpios = <0x2d 0x96 0x00>;
		interrupts = <0x00 0x33 0x01>;
		interrupt-names = "audio_exception64";
		status = "okay";

		aml-audio-card,dai-link@0 {
			format = "i2s";
			mclk-fs = <0x100>;
			continuous-clock;
			bitclock-master = <0xa7>;
			frame-master = <0xa7>;
			suffix-name = "alsaPORT-i2s";

			cpu {
				sound-dai = <0xa7>;
				dai-tdm-slot-tx-mask = <0x01 0x01>;
				dai-tdm-slot-rx-mask = <0x01 0x01>;
				dai-tdm-slot-num = <0x02>;
				dai-tdm-slot-width = <0x20>;
				system-clock-frequency = <0xbb8000>;
			};

			codec {
				prefix-names = "AMP\0AMP1";
				sound-dai = <0xa8 0xa9 0xaa>;
			};
		};

		aml-audio-card,dai-link@1 {
			format = "i2s";
			mclk-fs = <0x100>;
			bitclock-master = <0xab>;
			frame-master = <0xab>;
			suffix-name = "alsaPORT-pcm";

			cpu {
				sound-dai = <0xab>;
				dai-tdm-slot-tx-mask = <0x01 0x01>;
				dai-tdm-slot-rx-mask = <0x01 0x01>;
				dai-tdm-slot-num = <0x02>;
				dai-tdm-slot-width = <0x20>;
				system-clock-frequency = <0xbb8000>;
			};

			codec {
				sound-dai = <0xac>;
			};
		};

		aml-audio-card,dai-link@2 {
			format = "i2s";
			mclk-fs = <0x100>;
			bitclock-master = <0xad>;
			frame-master = <0xad>;

			cpu {
				sound-dai = <0xad>;
				dai-tdm-slot-tx-mask = <0x01 0x01>;
				dai-tdm-slot-rx-mask = <0x01 0x01>;
				dai-tdm-slot-num = <0x02>;
				dai-tdm-slot-width = <0x20>;
				system-clock-frequency = <0xbb8000>;
			};

			codec {
				sound-dai = <0xac>;
			};
		};

		aml-audio-card,dai-link@3 {
			mclk-fs = <0x40>;
			suffix-name = "alsaPORT-pdm";

			cpu {
				sound-dai = <0xae>;
			};

			codec {
				sound-dai = <0xac>;
			};
		};

		aml-audio-card,dai-link@4 {
			mclk-fs = <0x80>;
			continuous-clock;
			suffix-name = "alsaPORT-spdif";

			cpu {
				sound-dai = <0xaf>;
				system-clock-frequency = <0x5dc000>;
			};

			codec {
				sound-dai = <0xac>;
			};
		};

		aml-audio-card,dai-link@5 {
			mclk-fs = <0x80>;
			suffix-name = "alsaPORT-spdifb";

			cpu {
				sound-dai = <0xb0>;
				system-clock-frequency = <0x5dc000>;
			};

			codec {
				sound-dai = <0xac>;
			};
		};

		aml-audio-card,dai-link@6 {
			mclk-fs = <0x100>;
			suffix-name = "alsaPORT-tv";

			cpu {
				sound-dai = <0xb1>;
				system-clock-frequency = <0xbb8000>;
			};

			codec {
				sound-dai = <0xac>;
			};
		};

		aml-audio-card,dai-link@7 {
			mclk-fs = <0x100>;
			continuous-clock;
			suffix-name = "alsaPORT-loopback";

			cpu {
				sound-dai = <0xb2>;
				system-clock-frequency = <0xbb8000>;
			};

			codec {
				sound-dai = <0xac>;
			};
		};
	};

	picdec {
		compatible = "amlogic, picdec";
		status = "okay";
	};

	ppmgr {
		compatible = "amlogic, ppmgr";
		memory-region = <0xb3>;
		dev_name = "ppmgr";
		status = "okay";
	};

	ionvideo {
		compatible = "amlogic, ionvideo";
		dev_name = "ionvideo";
		status = "okay";
	};

	amlvideo2_0 {
		compatible = "amlogic, amlvideo2";
		dev_name = "amlvideo2";
		status = "okay";
		amlvideo2_id = <0x00>;
		cma_mode = <0x01>;
	};

	amlvideo2_1 {
		compatible = "amlogic, amlvideo2";
		dev_name = "amlvideo2";
		status = "okay";
		amlvideo2_id = <0x01>;
		cma_mode = <0x01>;
	};

	amdolby_vision {
		compatible = "amlogic, dolby_vision_t7";
		dev_name = "aml_amdolby_vision_driver";
		status = "okay";
		tv_mode = <0x01>;
	};

	adc_keypad {
		compatible = "amlogic, adc_keypad";
		status = "okay";
		key_name = "update\0vol-\0vol+\0enter";
		key_num = <0x04>;
		io-channels = <0xb4 0x02>;
		io-channel-names = "key-chan-2";
		key_chan = <0x02 0x02 0x02 0x02>;
		key_code = <0x8d 0x72 0x73 0x1c>;
		key_val = <0x00 0x8f 0x10a 0x185>;
		key_tolerance = <0x28 0x28 0x28 0x28>;
	};
};
